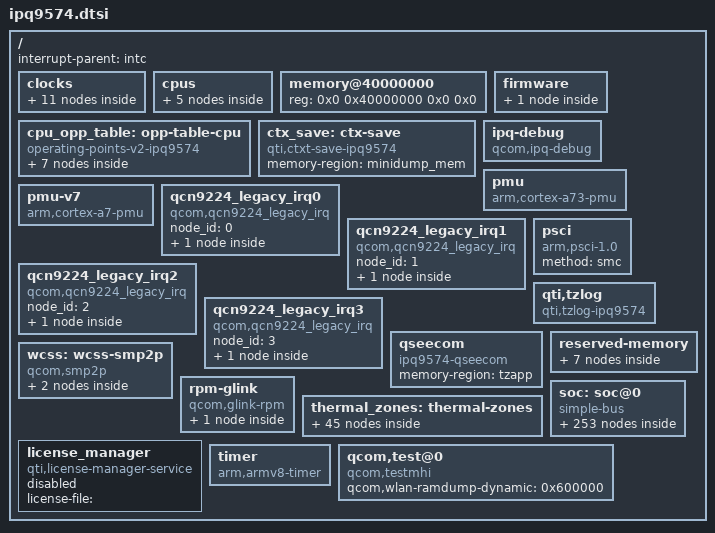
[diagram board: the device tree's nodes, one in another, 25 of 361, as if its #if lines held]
// SPDX-License-Identifier: (GPL-2.0+ OR BSD-3-Clause)
/*
 * IPQ9574 SoC device tree source
 *
 * Copyright (c) 2020-2021 The Linux Foundation. All rights reserved.
 * Copyright (c) 2022-2024 Qualcomm Innovation Center, Inc. All rights reserved.
 */

#include <dt-bindings/clock/qcom,apss-ipq.h>
#include <dt-bindings/clock/qcom,ipq9574-gcc.h>
#include <dt-bindings/interrupt-controller/arm-gic.h>
#include <dt-bindings/reset/qcom,ipq9574-gcc.h>
#include <dt-bindings/clock/qcom,nsscc-ipq9574.h>
#include <dt-bindings/reset/qcom,nsscc-ipq9574.h>


/ {
	interrupt-parent = <&intc>;
	#address-cells = <2>;
	#size-cells = <2>;

	clocks {
		bias_pll_ubi_nc_clk: bias-pll-ubi-nc-clk {
			compatible = "fixed-clock";
			clock-frequency = <353000000>;
			#clock-cells = <0>;
		};

		pcie30_phy0_pipe_clk: pcie30_phy0_pipe_clk {
			compatible = "fixed-clock";
			clock-frequency = <250000000>;
			#clock-cells = <0>;
		};

		pcie30_phy1_pipe_clk: pcie30_phy1_pipe_clk {
			compatible = "fixed-clock";
			clock-frequency = <250000000>;
			#clock-cells = <0>;
		};

		pcie30_phy2_pipe_clk: pcie30_phy2_pipe_clk {
			compatible = "fixed-clock";
			clock-frequency = <250000000>;
			#clock-cells = <0>;
		};

		pcie30_phy3_pipe_clk: pcie30_phy3_pipe_clk {
			compatible = "fixed-clock";
			clock-frequency = <250000000>;
			#clock-cells = <0>;
		};

		sleep_clk: sleep-clk {
			compatible = "fixed-clock";
			#clock-cells = <0>;
		};

		usb3phy_0_cc_pipe_clk: usb3phy_0_cc_pipe_clk {
			compatible = "fixed-clock";
			clock-frequency = <125000000>;
			#clock-cells = <0>;
		};

		xo: xo {
			compatible = "fixed-clock";
			#clock-cells = <0>;
		};

		bias_pll_cc_clk: bias_pll_cc_clk {
			compatible = "fixed-clock";
			clock-frequency = <1200000000>;
			#clock-cells = <0>;
		};

		bias_pll_nss_noc_clk: bias_pll_nss_noc_clk {
			compatible = "fixed-clock";
			clock-frequency = <461500000>;
			#clock-cells = <0>;
		};

		gcc_gpll0_out_aux: gcc_gpll0_out_aux {
			compatible = "fixed-clock";
			clock-frequency = <800000000>;
			#clock-cells = <0>;
		};
	};

	cpus {
		#address-cells = <1>;
		#size-cells = <0>;

		CPU0: cpu@0 {
			device_type = "cpu";
			compatible = "arm,cortex-a73";
			reg = <0x0>;
			enable-method = "psci";
			next-level-cache = <&L2_0>;
			clocks = <&apcs_glb APCS_ALIAS0_CORE_CLK>;
			clock-names = "cpu";
			operating-points-v2 = <&cpu_opp_table>;
			#cooling-cells = <2>;
		};

		CPU1: cpu@1 {
			device_type = "cpu";
			compatible = "arm,cortex-a73";
			reg = <0x1>;
			enable-method = "psci";
			next-level-cache = <&L2_0>;
			clocks = <&apcs_glb APCS_ALIAS0_CORE_CLK>;
			clock-names = "cpu";
			operating-points-v2 = <&cpu_opp_table>;
			#cooling-cells = <2>;
		};

		CPU2: cpu@2 {
			device_type = "cpu";
			compatible = "arm,cortex-a73";
			reg = <0x2>;
			enable-method = "psci";
			next-level-cache = <&L2_0>;
			clocks = <&apcs_glb APCS_ALIAS0_CORE_CLK>;
			clock-names = "cpu";
			operating-points-v2 = <&cpu_opp_table>;
			#cooling-cells = <2>;
		};

		CPU3: cpu@3 {
			device_type = "cpu";
			compatible = "arm,cortex-a73";
			reg = <0x3>;
			enable-method = "psci";
			next-level-cache = <&L2_0>;
			clocks = <&apcs_glb APCS_ALIAS0_CORE_CLK>;
			clock-names = "cpu";
			operating-points-v2 = <&cpu_opp_table>;
			#cooling-cells = <2>;
		};

		L2_0: l2-cache {
			compatible = "cache";
			cache-level = <2>;
		};
	};

	memory@40000000 {
		device_type = "memory";
		/* We expect the bootloader to fill in the size */
		reg = <0x0 0x40000000 0x0 0x0>;
	};

	cpu_opp_table: opp-table-cpu {
		compatible = "operating-points-v2-ipq9574";
		opp-shared;
		nvmem-cells = <&cpu_speed_bin>;
		nvmem-cell-names = "speed_bin";

		/* Listed all supported CPU frequencies and opp-supported-hw
		 * values to select CPU frequencies based on the limits fused.
		 * ------------------------------------------------------------
		 * Frequency     BIT3   BIT2   BIT1    BIT0    opp-supported-hw
		 *              1.2GHz 1.5GHz 1.8GHz No Limit
		 * ------------------------------------------------------------
		 * 936000000      1      1      1       1            0xF
		 * 1104000000     1      1      1       1            0xF
		 * 1200000000     1      0      0       0            0x8
		 * 1416000000     0      1      1       1            0x7
		 * 1488000000     0      1      0       0            0x4
		 * 1800000000     0      0      1       1            0x3
		 * 2208000000     0      0      0       1            0x1
		 * -----------------------------------------------------------*/

		opp-936000000 {
			opp-hz = /bits/ 64 <936000000>;
			opp-microvolt = <1>;
			opp-supported-hw = <0xF>;
			clock-latency-ns = <200000>;
		};

		opp-1104000000 {
			opp-hz = /bits/ 64 <1104000000>;
			opp-microvolt = <2>;
			opp-supported-hw = <0xF>;
			clock-latency-ns = <200000>;
		};

		opp-1200000000 {
			opp-hz = /bits/ 64 <1200000000>;
			opp-microvolt = <3>;
			opp-supported-hw = <0x8>;
			clock-latency-ns = <200000>;
		};

		opp-1416000000 {
			opp-hz = /bits/ 64 <1416000000>;
			opp-microvolt = <3>;
			opp-supported-hw = <0x7>;
			clock-latency-ns = <200000>;
		};

		opp-1488000000 {
			opp-hz = /bits/ 64 <1488000000>;
			opp-microvolt = <4>;
			opp-supported-hw = <0x7>;
			clock-latency-ns = <200000>;
		};

		opp-1800000000 {
			opp-hz = /bits/ 64 <1800000000>;
			opp-microvolt = <5>;
			opp-supported-hw = <0x3>;
			clock-latency-ns = <200000>;
		};

		opp-2208000000 {
			opp-hz = /bits/ 64 <2208000000>;
			opp-microvolt = <6>;
			opp-supported-hw = <0x1>;
			clock-latency-ns = <200000>;
		};
	};

	ctx_save: ctx-save {
		compatible = "qti,ctxt-save-ipq9574";
		memory-region = <&minidump_mem>;
	};

	firmware {
		scm {
			compatible = "qcom,scm-ipq9574", "qcom,scm";
			hvc-log-cmd-id = <0xA>;
			smmu-state-cmd-id = <0x20>;
			qcom,dload-mode = <&tcsr 0x6100>;
		};
	};

	ipq-debug {
		compatible = "qcom,ipq-debug";
	};

	pmu {
		compatible = "arm,cortex-a73-pmu";
		interrupts = <GIC_PPI 7 (GIC_CPU_MASK_SIMPLE(4) | IRQ_TYPE_LEVEL_HIGH)>;
	};

	pmu-v7 {
		compatible = "arm,cortex-a7-pmu";
		interrupts = <GIC_PPI 7 (GIC_CPU_MASK_SIMPLE(4) | IRQ_TYPE_LEVEL_HIGH)>;
	};

        qcn9224_legacy_irq0: qcn9224_legacy_irq0 {
		compatible = "qcom,qcn9224_legacy_irq";
		node_id = <0>;
		status = "okay";

		qcn9224_in0: legacy_interrupt {
			interrupt-controller;
			#interrupt-cells = <2>;
		};
	};

	qcn9224_legacy_irq1: qcn9224_legacy_irq1 {
		compatible = "qcom,qcn9224_legacy_irq";
		node_id = <1>;
		status = "okay";

		qcn9224_in1: legacy_interrupt {
			interrupt-controller;
			#interrupt-cells = <2>;
		};
	};

	qcn9224_legacy_irq2: qcn9224_legacy_irq2 {
		compatible = "qcom,qcn9224_legacy_irq";
		node_id = <2>;
		status = "okay";

		qcn9224_in2: legacy_interrupt {
			interrupt-controller;
			#interrupt-cells = <2>;
		};
	};

	qcn9224_legacy_irq3: qcn9224_legacy_irq3 {
		compatible = "qcom,qcn9224_legacy_irq";
		node_id = <3>;
		status = "okay";

		qcn9224_in3: legacy_interrupt {
			interrupt-controller;
			#interrupt-cells = <2>;
		};
	};

	psci {
		compatible = "arm,psci-1.0";
		method = "smc";
	};

	qti,tzlog {
		compatible = "qti,tzlog-ipq9574";
		interrupts = <GIC_SPI 244 IRQ_TYPE_EDGE_RISING>;
		qti,tz-diag-buf-size = <0x3000>;
		qti,tz-ring-off = <7>;
		qti,tz-log-pos-info-off = <810>;
		qti,hvc-enabled;
		qti,get-smmu-state;
	};

	qseecom: qseecom {
		compatible = "ipq9574-qseecom";
		memory-region = <&tzapp>;
		status = "okay";
	};

	reserved-memory {
		#address-cells = <2>;
		#size-cells = <2>;
		ranges;

		nss@40000000 {
			no-map;
			reg = <0x0 0x40000000 0x0 0x02000000>;
			status = "disabled";
		};

		tzapp:tzapp@49600000 {  /* TZAPPS */
		#if !defined(__IPQ_MEM_PROFILE_512_MB__)
			reg = <0x0 0x49600000 0x0 0x00600000>;
		#endif
			no-map;
		};

		bootloader@4a000000 {
			reg = <0x0 0x4a000000 0x0 0x00500000>;
			no-map;
		};

		sbl@4a500000 {
			reg = <0x0 0x4a500000 0x0 0x00100000>;
			no-map;
		};

		tz_region: tz@4a600000 {
			reg = <0x0 0x4a600000 0x0 0x400000>;
			no-map;
		};

		smem@4aa00000 {
			compatible = "qcom,smem";
			reg = <0x0 0x4aa00000 0x0 0x00100000>;
			hwlocks = <&tcsr_mutex 3>;
			no-map;
		};

		minidump_mem: minidump_mem@0 {
			no-map;
		};
	};

	wcss: wcss-smp2p {
		compatible = "qcom,smp2p";
		qcom,smem = <435>, <428>;

		interrupt-parent = <&intc>;
		interrupts = <GIC_SPI 322 IRQ_TYPE_EDGE_RISING>;

		mboxes = <&apcs_glb 9>;

		qcom,local-pid = <0>;
		qcom,remote-pid = <1>;

		wcss_smp2p_out: master-kernel {
			qcom,entry-name = "master-kernel";
			#qcom,smem-state-cells = <1>;
		};

		wcss_smp2p_in: slave-kernel {
			qcom,entry-name = "slave-kernel";
			interrupt-controller;
			#interrupt-cells = <2>;
		};
	};

	rpm-glink {
		compatible = "qcom,glink-rpm";
		interrupts = <GIC_SPI 168 IRQ_TYPE_EDGE_RISING>;
		qcom,rpm-msg-ram = <&rpm_msg_ram>;
		mboxes = <&apcs_glb 0>;

		rpm_requests: rpm-requests {
			compatible = "qcom,rpm-ipq9574";
			qcom,glink-channels = "rpm_requests";

		};
	};

	soc: soc@0 {
		compatible = "simple-bus";
		#address-cells = <1>;
		#size-cells = <1>;
		ranges = <0 0 0 0xffffffff>;

		qfprom {
			compatible = "qcom,qfprom-ipq9574-sec";
			img-addr = <0x4a100000>;
			img-size = <0x500000>;
			scm-cmd-id = <0x1f>;
			reg = <0xA6044 0x4>;
		};

		reg_update: reg-update@400000 {
			compatible = "ipq,reg-update";
			reg = <0x00400000 0x6148>,
			      <0x39d00020 0x10>;
			reg-names = "memnoc",
				    "ubicore";
			clocks = <&nsscc NSS_CC_NSS_CSR_CLK>,
				 <&nsscc NSS_CC_NSSNOC_NSS_CSR_CLK>;
			clock-names = "nss-csr-clk",
				      "nss-nssnoc-csr-clk";
			assigned-clocks = <&nsscc NSS_CC_NSS_CSR_CLK>,
					  <&nsscc NSS_CC_NSSNOC_NSS_CSR_CLK>;
			assigned-clock-rates = <100000000>,
					       <100000000>;
			status = "okay";
		};

		pcie0_phy: phy@84000 {
			compatible = "qcom,ipq9574-qmp-gen3x1-pcie-phy";
			reg = <0x00084000 0x1bc>; /* Serdes PLL */
			#address-cells = <1>;
			#size-cells = <1>;
			ranges;
			clocks = <&gcc GCC_PCIE0_AUX_CLK>,
				 <&gcc GCC_PCIE0_AHB_CLK>,
				 <&gcc GCC_ANOC_PCIE0_1LANE_M_CLK>,
				 <&gcc GCC_SNOC_PCIE0_1LANE_S_CLK>;
			clock-names = "aux", "cfg_ahb", "anoc_lane", "snoc_lane";

			assigned-clocks = <&gcc GCC_PCIE0_AUX_CLK>,
					  <&gcc GCC_PCIE0_AHB_CLK>,
					  <&gcc GCC_ANOC_PCIE0_1LANE_M_CLK>,
					  <&gcc GCC_SNOC_PCIE0_1LANE_S_CLK>;
			assigned-clock-rates = <20000000>,
					       <100000000>,
					       <240000000>,
					       <240000000>;

			resets = <&gcc GCC_PCIE0_PHY_BCR>,
				 <&gcc GCC_PCIE0PHY_PHY_BCR>;
			reset-names = "phy", "common";

			status = "disabled";

			pcie0_lane: phy@84200 {
				reg = <0x00084200 0x16c>, /* Serdes Tx */
				      <0x00084400 0x200>, /* Serdes Rx */
				      <0x00084800 0x1f0>, /* PCS: Lane0, COM, PCIE */
				      <0x00084c00 0xf4>;  /* pcs_misc */
				#phy-cells = <0>;

				clocks = <&gcc GCC_PCIE0_PIPE_CLK>;
				clock-names = "pipe0";
				clock-output-names = "gcc_pcie0_pipe_clk_src";
				#clock-cells = <0>;
			};
		};

		pcie2_phy: phy@8c000 {
			compatible = "qcom,ipq9574-qmp-gen3x2-pcie-phy";
			reg = <0x0008c000 0x1bc>; /* Serdes PLL */
			#address-cells = <1>;
			#size-cells = <1>;
			ranges;

			clocks = <&gcc GCC_PCIE2_AUX_CLK>,
				 <&gcc GCC_PCIE2_AHB_CLK>,
				 <&gcc GCC_ANOC_PCIE2_2LANE_M_CLK>,
				 <&gcc GCC_SNOC_PCIE2_2LANE_S_CLK>;
			clock-names = "aux", "cfg_ahb", "anoc_lane", "snoc_lane";

			assigned-clocks = <&gcc GCC_PCIE2_AUX_CLK>,
					  <&gcc GCC_PCIE2_AHB_CLK>,
					  <&gcc GCC_ANOC_PCIE2_2LANE_M_CLK>,
					  <&gcc GCC_SNOC_PCIE2_2LANE_S_CLK>;
			assigned-clock-rates = <20000000>,
					       <100000000>,
					       <342857143>,
					       <240000000>;

			resets = <&gcc GCC_PCIE2_PHY_BCR>,
				 <&gcc GCC_PCIE2PHY_PHY_BCR>;
			reset-names = "phy", "common";

			status = "disabled";

			pcie2_lanes: phy@8c200 {
				reg = <0x0008c200 0x16c>, /* Serdes Tx0 */
				      <0x0008c400 0x200>, /* Serdes Rx0 */
				      <0x0008d000 0x1f0>, /* PCS: Lane0, COM, PCIE */
				      <0x0008c600 0x16c>, /* Serdes Tx1 */
				      <0x0008c800 0x200>, /* Serdes Rx1 */
				      <0x0008d400 0x0f8>; /* pcs_misc */

				#phy-cells = <0>;

				clocks = <&gcc GCC_PCIE2_PIPE_CLK>;
				clock-names = "pipe0";
				clock-output-names = "gcc_pcie2_pipe_clk_src";
				#clock-cells = <0>;
			};
		};

		pcie3_phy: phy@f4000 {
			compatible = "qcom,ipq9574-qmp-gen3x2-pcie-phy";
			reg = <0x000f4000 0x1bc>; /* Serdes PLL */
			#address-cells = <1>;
			#size-cells = <1>;
			ranges;

			clocks = <&gcc GCC_PCIE3_AUX_CLK>,
				 <&gcc GCC_PCIE3_AHB_CLK>,
				 <&gcc GCC_ANOC_PCIE3_2LANE_M_CLK>,
				 <&gcc GCC_SNOC_PCIE3_2LANE_S_CLK>;
			clock-names = "aux", "cfg_ahb", "anoc_lane", "snoc_lane";

			assigned-clocks = <&gcc GCC_PCIE3_AUX_CLK>,
					  <&gcc GCC_PCIE3_AHB_CLK>,
					  <&gcc GCC_ANOC_PCIE3_2LANE_M_CLK>,
					  <&gcc GCC_SNOC_PCIE3_2LANE_S_CLK>;
			assigned-clock-rates = <20000000>,
					       <100000000>,
					       <342857143>,
					       <240000000>;

			resets = <&gcc GCC_PCIE3_PHY_BCR>,
				 <&gcc GCC_PCIE3PHY_PHY_BCR>;
			reset-names = "phy", "common";

			status = "disabled";

			pcie3_lanes: phy@f4200 {
				reg = <0x000f4200 0x16c>, /* Serdes Tx0 */
				      <0x000f4400 0x200>, /* Serdes Rx0 */
				      <0x000f5000 0x1f0>, /* PCS: Lane0, COM, PCIE */
				      <0x000f4600 0x16c>, /* Serdes Tx1 */
				      <0x000f4800 0x200>, /* Serdes Rx1 */
				      <0x000f5400 0x0f8>; /* pcs_misc */

				#phy-cells = <0>;

				clocks = <&gcc GCC_PCIE3_PIPE_CLK>;
				clock-names = "pipe0";
				clock-output-names = "gcc_pcie3_pipe_clk_src";
				#clock-cells = <0>;
			};
		};

		pcie1_phy: phy@fc000 {
			compatible = "qcom,ipq9574-qmp-gen3x1-pcie-phy";
			reg = <0x000fc000 0x1bc>; /* Serdes PLL */
			#address-cells = <1>;
			#size-cells = <1>;
			ranges;

			clocks = <&gcc GCC_PCIE1_AUX_CLK>,
			 <&gcc GCC_PCIE1_AHB_CLK>,
			 <&gcc GCC_ANOC_PCIE1_1LANE_M_CLK>,
				 <&gcc GCC_SNOC_PCIE1_1LANE_S_CLK>;
			clock-names = "aux", "cfg_ahb", "anoc_lane", "snoc_lane";

			assigned-clocks = <&gcc GCC_PCIE1_AUX_CLK>,
					  <&gcc GCC_PCIE1_AHB_CLK>,
					  <&gcc GCC_ANOC_PCIE1_1LANE_M_CLK>,
					  <&gcc GCC_SNOC_PCIE1_1LANE_S_CLK>;
			assigned-clock-rates = <20000000>,
					       <100000000>,
					       <240000000>,
					       <240000000>;

			resets = <&gcc GCC_PCIE1_PHY_BCR>,
				 <&gcc GCC_PCIE1PHY_PHY_BCR>;
			reset-names = "phy", "common";

			status = "disabled";

			pcie1_lane: phy@fc200 {
				reg = <0x000fc200 0x16c>, /* Serdes Tx */
				      <0x000fc400 0x200>, /* Serdes Rx */
				      <0x000fc800 0x1f0>, /* PCS: Lane0, COM, PCIE */
				      <0x000fcc00 0xf4>;  /* pcs_misc */
				#phy-cells = <0>;

				clocks = <&gcc GCC_PCIE1_PIPE_CLK>;
				clock-names = "pipe0";
				clock-output-names = "gcc_pcie1_pipe_clk_src";
				#clock-cells = <0>;
			};
		};

		qfprom@a4000 {
			compatible = "qcom,qfprom";
			reg = <0xA4000 0x5a1>;
			#address-cells = <1>;
			#size-cells = <1>;

			cpu_speed_bin: cpu_speed_bin@15 {
				reg = <0x15 0x2>;
				bits = <7 2>;
			};

			pcie0_disable: pcie0_disable@1c {
				reg = <0x1c 0x1>;
				bits = <2 1>;
			};

			pcie1_disable: pcie1_disable@1c {
				reg = <0x1c 0x1>;
				bits = <3 1>;
			};

			pcie2_disable: pcie2_disable@1c {
				reg = <0x1c 0x1>;
				bits = <4 1>;
			};

			pcie3_disable: pcie3_disable@1c {
				reg = <0x1c 0x1>;
				bits = <5 1>;
			};
		};

		rng: rng@e3000 {
			compatible = "qcom,prng-ee";
			reg = <0x000e3000 0x1000>;
			clocks = <&gcc GCC_PRNG_AHB_CLK>;
			clock-names = "core";
		};

		cryptobam: dma@704000 {
			compatible = "qcom,bam-v1.7.0";
			reg = <0x00704000 0x20000>;
			interrupts = <GIC_SPI 207 IRQ_TYPE_LEVEL_HIGH>;
			#dma-cells = <1>;
			qcom,ee = <1>;
			qcom,controlled-remotely;
		};

		crypto: crypto@73a000 {
			compatible = "qcom,crypto-v5.1";
			reg = <0x0073a000 0x6000>;
			clocks = <&gcc GCC_CRYPTO_AHB_CLK>,
				 <&gcc GCC_CRYPTO_AXI_CLK>,
				 <&gcc GCC_CRYPTO_CLK>;
			clock-names = "iface", "bus", "core";
			dmas = <&cryptobam 2>, <&cryptobam 3>;
			dma-names = "rx", "tx";
			qce,cmd_desc_support;
		};

		rpm_msg_ram: sram@60000 {
			compatible = "qcom,rpm-msg-ram";
			reg = <0x00060000 0x6000>;
		};

		tsens: thermal-sensor@4a9000 {
			compatible = "qcom,ipq9574-tsens", "qcom,ipq8074-tsens";
			reg = <0x004a9000 0x1000>,
			      <0x004a8000 0x1000>;
			interrupts = <GIC_SPI 184 IRQ_TYPE_EDGE_RISING>;
			interrupt-names = "combined";
			#qcom,sensors = <16>;
			#thermal-sensor-cells = <1>;
		};

		tlmm: pinctrl@1000000 {
			compatible = "qcom,ipq9574-tlmm";
			reg = <0x01000000 0x300000>;
			interrupts = <GIC_SPI 208 IRQ_TYPE_LEVEL_HIGH>;
			gpio-controller;
			#gpio-cells = <2>;
			gpio-ranges = <&tlmm 0 0 65>;
			interrupt-controller;
			#interrupt-cells = <2>;

			uart2_pins: uart2-state {
				pins = "gpio34", "gpio35";
				function = "blsp2_uart";
				drive-strength = <8>;
				bias-disable;
			};

			gps_pins: gps_pins {
                                blsp3_uart_pinmux {
                                        pins = "gpio17", "gpio18";
                                        function = "blsp3_uart";
                                        drive-strength = <8>;
                                        bias-disable;
                                };

                                gps_on_off {
                                        pins = "gpio7";
                                        function = "gpio";
                                        drive-strength = <8>;
                                        bias-pull-down;
                                };
                        };

			mdio_pins: mdio-state {
				mux_0 {
					pins = "gpio38";
					function = "mdc";
					drive-strength = <8>;
					bias-disable;
				};

				mux_1 {
					pins = "gpio39";
					function = "mdio";
					drive-strength = <8>;
					bias-pull-up;
				};
			};
		};

		gcc: clock-controller@1800000 {
			compatible = "qcom,ipq9574-gcc";
			reg = <0x01800000 0x80000>;
			clocks = <&xo>,
				 <&sleep_clk>,
				 <&bias_pll_ubi_nc_clk>,
				 <&pcie30_phy0_pipe_clk>,
				 <&pcie30_phy1_pipe_clk>,
				 <&pcie30_phy2_pipe_clk>,
				 <&pcie30_phy3_pipe_clk>,
				 <&usb3phy_0_cc_pipe_clk>;
			#clock-cells = <1>;
			#reset-cells = <1>;
			#power-domain-cells = <1>;
		};

                nsscc: nsscc@39b00000 {
			compatible = "qcom,nsscc-ipq9574";
			reg = <0x39b00000 0x80000>;
			clocks = <&bias_pll_cc_clk>,
				 <&bias_pll_nss_noc_clk>,
				 <&bias_pll_ubi_nc_clk>,
				 <&gcc_gpll0_out_aux>,
				 <&xo>;
			clock-names = "bias_pll_cc_clk",
				      "bias_pll_nss_noc_clk",
				      "bias_pll_ubi_nc_clk",
				      "gcc_gpll0_out_aux",
				      "xo";
			#clock-cells = <0x1>;
			#reset-cells = <0x1>;
		};

		dcc@797f000 {
			compatible = "qcom,dcc-v2";
			reg = <0x797F000 0x1000>,
			      <0x7906000 0x1000>;
			reg-names = "dcc-base", "dcc-ram-base";

			dcc-ram-offset = <0x6000>;
			status = "okay";
		};

		qpic_bam: dma@7984000 {
			compatible = "qcom,bam-v1.7.0";
			reg = <0x7984000 0x1c000>;
			interrupts = <GIC_SPI 146 IRQ_TYPE_LEVEL_HIGH>;
			clocks = <&gcc GCC_QPIC_AHB_CLK>;
			clock-names = "bam_clk";
			#dma-cells = <1>;
			qcom,ee = <0>;
			status = "disabled";
		};

		qpic_nand: nand@79b0000 {
			compatible = "qcom,ipq9574-nand";
			reg = <0x79b0000 0x10000>;
			#address-cells = <1>;
			#size-cells = <0>;
			clocks = <&gcc GCC_QPIC_CLK>,
			<&gcc GCC_QPIC_AHB_CLK>,
			<&gcc GCC_QPIC_IO_MACRO_CLK>;
			clock-names = "core", "aon", "io_macro";

			dmas = <&qpic_bam 0>,
				<&qpic_bam 1>,
				<&qpic_bam 2>,
				<&qpic_bam 3>;
			dma-names = "tx", "rx", "cmd", "sts";
			status = "disabled";
		};

		lpass: lpass@0xA000000{
			compatible = "qca,lpass-ipq9574";
			reg =  <0xA000000 0x3BFFFF>;
			clocks = <&gcc GCC_LPASS_SWAY_CLK>,
			<&gcc GCC_LPASS_CORE_AXIM_CLK>,
			<&gcc GCC_SNOC_LPASS_CFG_CLK>,
			<&gcc GCC_PCNOC_LPASS_CLK>;
			clock-names = "sway", "axim", "snoc_cfg", "pcnoc";
			resets = <&gcc GCC_LPASS_BCR>;
			reset-names = "lpass";
			status = "disabled";
		};

		pcm: pcm@0xA3C0000{
			compatible = "qca,ipq9574-lpass-pcm";
			reg =  <0xA3C0000 0x23014>;
			status = "disabled";

			pcm0: pcm0@0 {
				interrupts = <0 419 IRQ_TYPE_LEVEL_HIGH>;
				interrupt-names = "out0";
				capture_memory = "lpm";
				playback_memory = "lpm";
				voice_loopback = <0>;
				slave = <0>;
				status = "disabled";
			      };

			pcm1: pcm1@1 {
				interrupts = <0 117 IRQ_TYPE_LEVEL_HIGH>;
				interrupt-names = "out1";
				capture_memory = "lpm";
				playback_memory = "lpm";
				voice_loopback = <0>;
				slave = <0>;
				status = "disabled";
			};

		};

		pcm_lb: pcm_lb@0 {
			compatible = "qca,ipq9574-pcm-lb";
			status = "disabled";
		};

		wsi: wsi {
			status = "disabled";
		};

		pcie1_x1: pci@10000000 {
			compatible = "qti,pcie-ipq9574";
			reg =  <0x10000000 0xf1d>,
			       <0x10000F20 0xa8>,
			       <0x10001000 0x1000>,
			       <0x000F8000 0x4000>,
			       <0x10100000 0x1000>,
			       <0x00618108 0x4>;
			reg-names = "dbi", "elbi", "atu", "parf", "config", "aggr_noc";
			device_type = "pci";
			linux,pci-domain = <1>;
			bus-range = <0x00 0xff>;
			num-lanes = <1>;
			#address-cells = <3>;
			#size-cells = <2>;
			axi-halt-val = <0x1e>; /* increase halt window size to 1GB */

			ranges = <0x81000000 0 0x10200000 0x10200000
				  0 0x00100000   /* downstream I/O */
				  0x82000000 0 0x10300000 0x10300000
				  0 0x07d00000>; /* non-prefetchable memory */

			#interrupt-cells = <1>;
			interrupt-map-mask = <0 0 0 0x7>;
			interrupt-map = <0 0 0 1 &intc 0 35
					IRQ_TYPE_LEVEL_HIGH>, /* int_a */
					<0 0 0 2 &intc 0 49
					IRQ_TYPE_LEVEL_HIGH>, /* int_b */
					<0 0 0 3 &intc 0 84
					IRQ_TYPE_LEVEL_HIGH>, /* int_c */
					<0 0 0 4 &intc 0 85
					IRQ_TYPE_LEVEL_HIGH>; /* int_d */

			interrupts = <GIC_SPI 25 IRQ_TYPE_LEVEL_HIGH>;
			interrupt-names = "global_irq";

			/* clocks and clock-names are used to enable the clock in CBCR */
			clocks = <&gcc GCC_PCIE1_AHB_CLK>,
				 <&gcc GCC_PCIE1_AUX_CLK>,
				 <&gcc GCC_PCIE1_AXI_M_CLK>,
				 <&gcc GCC_PCIE1_AXI_S_CLK>,
				 <&gcc GCC_PCIE1_AXI_S_BRIDGE_CLK>,
				 <&gcc GCC_PCIE1_RCHNG_CLK>;
			clock-names = "ahb",
				      "aux",
				      "axi_m",
				      "axi_s",
				      "axi_bridge",
				      "rchng";

			assigned-clocks = <&gcc GCC_PCIE1_AHB_CLK>,
					  <&gcc GCC_PCIE1_AUX_CLK>,
				    	  <&gcc GCC_PCIE1_AXI_M_CLK>,
					  <&gcc GCC_PCIE1_AXI_S_CLK>,
					  <&gcc GCC_PCIE1_AXI_S_BRIDGE_CLK>,
					  <&gcc GCC_PCIE1_RCHNG_CLK>;
			assigned-clock-rates = <100000000>,
					       <20000000>,
					       <240000000>,
					       <240000000>,
					       <240000000>,
					       <100000000>;

			resets = <&gcc GCC_PCIE1_PIPE_ARES>,
				 <&gcc GCC_PCIE1_CORE_STICKY_ARES>,
				 <&gcc GCC_PCIE1_AXI_S_STICKY_ARES>,
				 <&gcc GCC_PCIE1_AXI_S_ARES>,
				 <&gcc GCC_PCIE1_AXI_M_STICKY_ARES>,
				 <&gcc GCC_PCIE1_AXI_M_ARES>,
				 <&gcc GCC_PCIE1_AUX_ARES>,
				 <&gcc GCC_PCIE1_AHB_ARES>;
			reset-names = "pipe",
				      "sticky",
				      "axi_s_sticky",
				      "axi_s",
				      "axi_m_sticky",
				      "axi_m",
				      "aux",
				      "ahb";

			phys = <&pcie1_lane>;
			phy-names = "pciephy";
			msi-parent = <&v2m0>;
			nvmem-cells = <&pcie1_disable>;
			status = "disabled";
		};

		pcie3_x2: pci@18000000 {
			compatible = "qti,pcie-ipq9574";
			reg =  <0x18000000 0xf1d>,
			       <0x18000F20 0xa8>,
			       <0x18001000 0x1000>,
			       <0x000F0000 0x4000>,
			       <0x18100000 0x1000>;
			reg-names = "dbi", "elbi", "atu", "parf", "config";
			device_type = "pci";
			linux,pci-domain = <3>;
			bus-range = <0x00 0xff>;
			num-lanes = <2>;
			#address-cells = <3>;
			#size-cells = <2>;
			axi-halt-val = <0x1e>; /* increase halt window size to 1GB */

			ranges = <0x81000000 0 0x18200000 0x18200000
				  0 0x00100000   /* downstream I/O */
				  0x82000000 0 0x18300000 0x18300000
				  0 0x07d00000>; /* non-prefetchable memory */

			#interrupt-cells = <1>;
			interrupt-map-mask = <0 0 0 0x7>;
			interrupt-map = <0 0 0 1 &intc 0 189
					 IRQ_TYPE_LEVEL_HIGH>, /* int_a */
					<0 0 0 2 &intc 0 190
					 IRQ_TYPE_LEVEL_HIGH>, /* int_b */
					<0 0 0 3 &intc 0 191
					 IRQ_TYPE_LEVEL_HIGH>, /* int_c */
					<0 0 0 4 &intc 0 192
					 IRQ_TYPE_LEVEL_HIGH>; /* int_d */

			interrupts = <GIC_SPI 188 IRQ_TYPE_LEVEL_HIGH>;
			interrupt-names = "global_irq";

			/* clocks and clock-names are used to enable the clock in CBCR */
			clocks = <&gcc GCC_PCIE3_AHB_CLK>,
				 <&gcc GCC_PCIE3_AUX_CLK>,
				 <&gcc GCC_PCIE3_AXI_M_CLK>,
				 <&gcc GCC_PCIE3_AXI_S_CLK>,
				 <&gcc GCC_PCIE3_AXI_S_BRIDGE_CLK>,
				 <&gcc GCC_PCIE3_RCHNG_CLK>;
			clock-names = "ahb",
				      "aux",
				      "axi_m",
				      "axi_s",
				      "axi_bridge",
				      "rchng";

			assigned-clocks = <&gcc GCC_PCIE3_AHB_CLK>,
					  <&gcc GCC_PCIE3_AUX_CLK>,
					  <&gcc GCC_PCIE3_AXI_M_CLK>,
					  <&gcc GCC_PCIE3_AXI_S_CLK>,
					  <&gcc GCC_PCIE3_AXI_S_BRIDGE_CLK>,
					  <&gcc GCC_PCIE3_RCHNG_CLK>;
			assigned-clock-rates = <100000000>,
					       <20000000>,
					       <342857143>,
					       <240000000>,
					       <240000000>,
					       <100000000>;

			resets = <&gcc GCC_PCIE3_PIPE_ARES>,
				 <&gcc GCC_PCIE3_CORE_STICKY_ARES>,
				 <&gcc GCC_PCIE3_AXI_S_STICKY_ARES>,
				 <&gcc GCC_PCIE3_AXI_S_ARES>,
				 <&gcc GCC_PCIE3_AXI_M_STICKY_ARES>,
				 <&gcc GCC_PCIE3_AXI_M_ARES>,
				 <&gcc GCC_PCIE3_AUX_ARES>,
				 <&gcc GCC_PCIE3_AHB_ARES>;
			reset-names = "pipe",
				      "sticky",
				      "axi_s_sticky",
				      "axi_s",
				      "axi_m_sticky",
				      "axi_m",
				      "aux",
				      "ahb";

			phys = <&pcie3_lanes>;
			phy-names = "pciephy";
			msi-parent = <&v2m0>;
			nvmem-cells = <&pcie3_disable>;
			status = "disabled";
		};

		pcie2_x2: pci@20000000 {
			compatible = "qti,pcie-ipq9574";
			reg =  <0x20000000 0xf1d>,
			       <0x20000F20 0xa8>,
			       <0x20001000 0x1000>,
			       <0x00088000 0x4000>,
			       <0x20100000 0x1000>;
			reg-names = "dbi", "elbi", "atu", "parf", "config";
			device_type = "pci";
			linux,pci-domain = <2>;
			bus-range = <0x00 0xff>;
			num-lanes =<2>;
			#address-cells = <3>;
			#size-cells = <2>;
			axi-halt-val = <0x1e>; /* increase halt window size to 1GB */

			ranges = <0x81000000 0 0x20200000 0x20200000
				  0 0x00100000   /* downstream I/O */
				  0x82000000 0 0x20300000 0x20300000
				  0 0x07d00000>; /* non-prefetchable memory */

			#interrupt-cells = <1>;
			interrupt-map-mask = <0 0 0 0x7>;
			interrupt-map = <0 0 0 1 &intc 0 164
					 IRQ_TYPE_LEVEL_HIGH>, /* int_a */
					<0 0 0 2 &intc 0 165
					 IRQ_TYPE_LEVEL_HIGH>, /* int_b */
					<0 0 0 3 &intc 0 186
					 IRQ_TYPE_LEVEL_HIGH>, /* int_c */
					<0 0 0 4 &intc 0 187
					 IRQ_TYPE_LEVEL_HIGH>; /* int_d */

			interrupts = <GIC_SPI 125 IRQ_TYPE_LEVEL_HIGH>;
			interrupt-names = "global_irq";

			/* clocks and clock-names are used to enable the clock in CBCR */
			clocks = <&gcc GCC_PCIE2_AHB_CLK>,
				 <&gcc GCC_PCIE2_AUX_CLK>,
				 <&gcc GCC_PCIE2_AXI_M_CLK>,
				 <&gcc GCC_PCIE2_AXI_S_CLK>,
				 <&gcc GCC_PCIE2_AXI_S_BRIDGE_CLK>,
				 <&gcc GCC_PCIE2_RCHNG_CLK>;
			clock-names = "ahb",
				      "aux",
				      "axi_m",
				      "axi_s",
				      "axi_bridge",
				      "rchng";

			assigned-clocks = <&gcc GCC_PCIE2_AHB_CLK>,
					  <&gcc GCC_PCIE2_AUX_CLK>,
					  <&gcc GCC_PCIE2_AXI_M_CLK>,
					  <&gcc GCC_PCIE2_AXI_S_CLK>,
					  <&gcc GCC_PCIE2_AXI_S_BRIDGE_CLK>,
					  <&gcc GCC_PCIE2_RCHNG_CLK>;
			assigned-clock-rates = <100000000>,
					       <20000000>,
					       <342857143>,
					       <240000000>,
					       <240000000>,
					       <100000000>;

			resets = <&gcc GCC_PCIE2_PIPE_ARES>,
				 <&gcc GCC_PCIE2_CORE_STICKY_ARES>,
				 <&gcc GCC_PCIE2_AXI_S_STICKY_ARES>,
				 <&gcc GCC_PCIE2_AXI_S_ARES>,
				 <&gcc GCC_PCIE2_AXI_M_STICKY_ARES>,
				 <&gcc GCC_PCIE2_AXI_M_ARES>,
				 <&gcc GCC_PCIE2_AUX_ARES>,
				 <&gcc GCC_PCIE2_AHB_ARES>;
			reset-names = "pipe",
				      "sticky",
				      "axi_s_sticky",
				      "axi_s",
				      "axi_m_sticky",
				      "axi_m",
				      "aux",
				      "ahb";

			phys = <&pcie2_lanes>;
			phy-names = "pciephy";
			msi-parent = <&v2m0>;
			nvmem-cells = <&pcie2_disable>;
			status = "disabled";
		};

		pcie0_x1: pci@28000000 {
			compatible = "qti,pcie-ipq9574";
			reg =  <0x28000000 0xf1d>,
			       <0x28000F20 0xa8>,
			       <0x28001000 0x1000>,
			       <0x00080000 0x4000>,
			       <0x28100000 0x1000>,
			       <0x00618088 0x4>;
			reg-names = "dbi", "elbi", "atu", "parf", "config", "aggr_noc";
			device_type = "pci";
			linux,pci-domain = <0>;
			bus-range = <0x00 0xff>;
			num-lanes = <1>;
			#address-cells = <3>;
			#size-cells = <2>;
			axi-halt-val = <0x1e>; /* increase halt window size to 1GB */

			ranges = <0x81000000 0 0x28200000 0x28200000
				  0 0x00100000   /* downstream I/O */
				  0x82000000 0 0x28300000 0x28300000
				  0 0x07d00000>; /* non-prefetchable memory */

			#interrupt-cells = <1>;
			interrupt-map-mask = <0 0 0 0x7>;
			interrupt-map = <0 0 0 1 &intc 0 75
					 IRQ_TYPE_LEVEL_HIGH>, /* int_a */
					<0 0 0 2 &intc 0 78
					 IRQ_TYPE_LEVEL_HIGH>, /* int_b */
					<0 0 0 3 &intc 0 79
					 IRQ_TYPE_LEVEL_HIGH>, /* int_c */
					<0 0 0 4 &intc 0 83
					 IRQ_TYPE_LEVEL_HIGH>; /* int_d */

			interrupts = <GIC_SPI 51 IRQ_TYPE_LEVEL_HIGH>;
			interrupt-names = "global_irq";

			/* clocks and clock-names are used to enable the clock in CBCR */
			clocks = <&gcc GCC_PCIE0_AHB_CLK>,
				 <&gcc GCC_PCIE0_AUX_CLK>,
				 <&gcc GCC_PCIE0_AXI_M_CLK>,
				 <&gcc GCC_PCIE0_AXI_S_CLK>,
				 <&gcc GCC_PCIE0_AXI_S_BRIDGE_CLK>,
				 <&gcc GCC_PCIE0_RCHNG_CLK>;
			clock-names = "ahb",
				      "aux",
				      "axi_m",
				      "axi_s",
				      "axi_bridge",
				      "rchng";

			assigned-clocks = <&gcc GCC_PCIE0_AHB_CLK>,
					  <&gcc GCC_PCIE0_AUX_CLK>,
					  <&gcc GCC_PCIE0_AXI_M_CLK>,
					  <&gcc GCC_PCIE0_AXI_S_CLK>,
					  <&gcc GCC_PCIE0_AXI_S_BRIDGE_CLK>,
					  <&gcc GCC_PCIE0_RCHNG_CLK>;
			assigned-clock-rates = <100000000>,
					       <20000000>,
					       <240000000>,
					       <240000000>,
					       <240000000>,
					       <100000000>;

			resets = <&gcc GCC_PCIE0_PIPE_ARES>,
				 <&gcc GCC_PCIE0_CORE_STICKY_ARES>,
				 <&gcc GCC_PCIE0_AXI_S_STICKY_ARES>,
				 <&gcc GCC_PCIE0_AXI_S_ARES>,
				 <&gcc GCC_PCIE0_AXI_M_STICKY_ARES>,
				 <&gcc GCC_PCIE0_AXI_M_ARES>,
				 <&gcc GCC_PCIE0_AUX_ARES>,
				 <&gcc GCC_PCIE0_AHB_ARES>;
			reset-names = "pipe",
				      "sticky",
				      "axi_s_sticky",
				      "axi_s",
				      "axi_m_sticky",
				      "axi_m",
				      "aux",
				      "ahb";

			phys = <&pcie0_lane>;
			phy-names = "pciephy";
			msi-parent = <&v2m0>;
			nvmem-cells = <&pcie0_disable>;
			status = "disabled";
		};

		qti,rpm-log@29fc00 {
			compatible = "qti,rpm-log";
			reg = <0x29fc00 0x4000>;
			qti,rpm-addr-phys = <0x200000>;
			qti,offset-version = <4>;
			qti,offset-page-buffer-addr = <36>;
			qti,offset-log-len = <40>;
			qti,offset-log-len-mask = <44>;
			qti,offset-page-indices = <56>;
		};

		wifi0: wifi@c0000000 {
			compatible = "qcom,cnss-qca9574", "qcom,ipq9574-wifi";
			reg = <0xc000000 0x1000000>;
			qcom,hw-mode-id = <1>;
		#ifdef __IPQ_MEM_PROFILE_256_MB__
			qcom,tgt-mem-mode = <2>;
		#elif __IPQ_MEM_PROFILE_512_MB__
			qcom,tgt-mem-mode = <1>;
		#else
			qcom,tgt-mem-mode = <0>;
		#endif
			qcom,rproc = <&q6v5_wcss>;
			qcom,bdf-addr = <0x4b700000 0x4b700000 0x4b700000
					 0x0 0x0 0x0>;
			qcom,caldb-addr = <0x4d800000 0x4ca00000 0x0
					   0x0 0x0 0x0>;
			qcom,caldb-size = <0x500000>;
		#ifdef __IPQ_MEM_PROFILE_512_MB__
			m3-dump-addr = <0x4c800000>;
		#else
			m3-dump-addr = <0x4d600000>;
		#endif
			interrupts = <GIC_SPI 320 IRQ_TYPE_EDGE_RISING>, /* o_wcss_apps_intr[0] =  */
				<GIC_SPI 319 IRQ_TYPE_EDGE_RISING>,
				<GIC_SPI 318 IRQ_TYPE_EDGE_RISING>,
				<GIC_SPI 316 IRQ_TYPE_EDGE_RISING>,
				<GIC_SPI 315 IRQ_TYPE_EDGE_RISING>,
				<GIC_SPI 314 IRQ_TYPE_EDGE_RISING>,
				<GIC_SPI 311 IRQ_TYPE_EDGE_RISING>,
				<GIC_SPI 310 IRQ_TYPE_EDGE_RISING>,
				<GIC_SPI 411 IRQ_TYPE_EDGE_RISING>,
				<GIC_SPI 410 IRQ_TYPE_EDGE_RISING>,
				<GIC_SPI 40 IRQ_TYPE_EDGE_RISING>,
				<GIC_SPI 39 IRQ_TYPE_EDGE_RISING>,
				<GIC_SPI 302 IRQ_TYPE_EDGE_RISING>,
				<GIC_SPI 301 IRQ_TYPE_EDGE_RISING>,
				<GIC_SPI 37 IRQ_TYPE_EDGE_RISING>,
				<GIC_SPI 36 IRQ_TYPE_EDGE_RISING>,
				<GIC_SPI 296 IRQ_TYPE_EDGE_RISING>,
				<GIC_SPI 295 IRQ_TYPE_EDGE_RISING>,
				<GIC_SPI 294 IRQ_TYPE_EDGE_RISING>,
				<GIC_SPI 293 IRQ_TYPE_EDGE_RISING>,
				<GIC_SPI 292 IRQ_TYPE_EDGE_RISING>,
				<GIC_SPI 291 IRQ_TYPE_EDGE_RISING>,
				<GIC_SPI 290 IRQ_TYPE_EDGE_RISING>,
				<GIC_SPI 289 IRQ_TYPE_EDGE_RISING>,
				<GIC_SPI 288 IRQ_TYPE_EDGE_RISING>, /* o_wcss_apps_intr[25] */
				<GIC_SPI 239 IRQ_TYPE_EDGE_RISING>,
				<GIC_SPI 236 IRQ_TYPE_EDGE_RISING>,
				<GIC_SPI 235 IRQ_TYPE_EDGE_RISING>,
				<GIC_SPI 234 IRQ_TYPE_EDGE_RISING>,
				<GIC_SPI 233 IRQ_TYPE_EDGE_RISING>,
				<GIC_SPI 232 IRQ_TYPE_EDGE_RISING>,
				<GIC_SPI 231 IRQ_TYPE_EDGE_RISING>,
				<GIC_SPI 230 IRQ_TYPE_EDGE_RISING>,
				<GIC_SPI 229 IRQ_TYPE_EDGE_RISING>,
				<GIC_SPI 228 IRQ_TYPE_EDGE_RISING>,
				<GIC_SPI 224 IRQ_TYPE_EDGE_RISING>,
				<GIC_SPI 223 IRQ_TYPE_EDGE_RISING>,
				<GIC_SPI 203 IRQ_TYPE_EDGE_RISING>,
				<GIC_SPI 183 IRQ_TYPE_EDGE_RISING>,
				<GIC_SPI 180 IRQ_TYPE_EDGE_RISING>,
				<GIC_SPI 179 IRQ_TYPE_EDGE_RISING>,
				<GIC_SPI 178 IRQ_TYPE_EDGE_RISING>,
				<GIC_SPI 177 IRQ_TYPE_EDGE_RISING>,
				<GIC_SPI 176 IRQ_TYPE_EDGE_RISING>,
				<GIC_SPI 163 IRQ_TYPE_EDGE_RISING>,
				<GIC_SPI 162 IRQ_TYPE_EDGE_RISING>,
				<GIC_SPI 160 IRQ_TYPE_EDGE_RISING>,
				<GIC_SPI 414 IRQ_TYPE_EDGE_RISING>,
				<GIC_SPI 159 IRQ_TYPE_EDGE_RISING>,
				<GIC_SPI 158 IRQ_TYPE_EDGE_RISING>,
				<GIC_SPI 157 IRQ_TYPE_EDGE_RISING>,
				<GIC_SPI 156 IRQ_TYPE_EDGE_RISING>; /* o_wcss_apps_intr[51] */

			interrupt-names = "misc-pulse1",
				"misc-latch",
				"sw-exception",
				"ce0",
				"ce1",
				"ce2",
				"ce3",
				"ce4",
				"ce5",
				"ce6",
				"ce7",
				"ce8",
				"ce9",
				"ce10",
				"ce11",
				"host2wbm-desc-feed",
				"host2reo-re-injection",
				"host2reo-command",
				"host2rxdma-monitor-ring3",
				"host2rxdma-monitor-ring2",
				"host2rxdma-monitor-ring1",
				"reo2ost-exception",
				"wbm2host-rx-release",
				"reo2host-status",
				"reo2host-destination-ring4",
				"reo2host-destination-ring3",
				"reo2host-destination-ring2",
				"reo2host-destination-ring1",
				"rxdma2host-monitor-destination-mac3",
				"rxdma2host-monitor-destination-mac2",
				"rxdma2host-monitor-destination-mac1",
				"ppdu-end-interrupts-mac3",
				"ppdu-end-interrupts-mac2",
				"ppdu-end-interrupts-mac1",
				"rxdma2host-monitor-status-ring-mac3",
				"rxdma2host-monitor-status-ring-mac2",
				"rxdma2host-monitor-status-ring-mac1",
				"host2rxdma-host-buf-ring-mac3",
				"host2rxdma-host-buf-ring-mac2",
				"host2rxdma-host-buf-ring-mac1",
				"rxdma2host-destination-ring-mac3",
				"rxdma2host-destination-ring-mac2",
				"rxdma2host-destination-ring-mac1",
				"host2tcl-input-ring4",
				"host2tcl-input-ring3",
				"host2tcl-input-ring2",
				"host2tcl-input-ring1",
				"wbm2host-tx-completions-ring4",
				"wbm2host-tx-completions-ring3",
				"wbm2host-tx-completions-ring2",
				"wbm2host-tx-completions-ring1",
				"tcl2host-status-ring";

			qcom,pta-num = <0>;
			qcom,coex-mode = <0x2>;
			qcom,bt-active-time = <0x12>;
			qcom,bt-priority-time = <0x0c>;
			qcom,coex-algo = <0x2>;
			qcom,pta-priority = <0x80800505>;
			status = "disabled";
		};

		wifi1: wifi1@f00000 {
			compatible  = "qcom,cnss-qcn9000";
			qcom,wlan-ramdump-dynamic = <0x400000>;
			qrtr_node_id = <0x20>;
			qca,auto-restart;
			interrupt-bmap = <0x100503>;
			status = "disabled";
		};

		wifi2: wifi2@f00000 {
			compatible  = "qcom,cnss-qcn9000";
			qcom,wlan-ramdump-dynamic = <0x400000>;
			qrtr_node_id = <0x21>;
			qca,auto-restart;
			interrupt-bmap = <0x100503>;
			status = "disabled";
		};

		wifi3: wifi3@f00000 {
			compatible  = "qcom,cnss-qcn9000";
			qcom,wlan-ramdump-dynamic = <0x400000>;
			qrtr_node_id = <0x22>;
			qca,auto-restart;
			interrupt-bmap = <0x100503>;
			status = "disabled";
		};

		wifi4: wifi4@f00000 {
			compatible  = "qcom,cnss-qcn9224";
			qcom,wlan-ramdump-dynamic = <0x600000>;
			qca,auto-restart;
			interrupt-bmap = <0x100512>;
#ifdef __IPQ_MEM_PROFILE_512_MB__
			/* qcn9224 tgt-mem-mode=1 layout - 37MB
			 * +=========+==============+=========+
			 * |  Region | Start Offset |   Size  |
			 * +---------+--------------+---------+
			 * | HREMOTE |  0x4CF00000  |   20MB  |
			 * +---------+--------------+---------+
			 * | M3 Dump |  0x4E300000  |   1MB   |
			 * +---------+--------------+---------+
			 * |   ETR   |  0x4E400000  |   1MB   |
			 * +---------+--------------+---------+
			 * |  Caldb  |  0x4E500000  |   8MB   |
			 * +---------+--------------+---------+
			 * |Pageable |  0x4ED00000  |   7MB   |
			 * +==================================+
			 */
			base-addr = <0x4CF00000>;
			m3-dump-addr = <0x4E300000>;
			etr-addr = <0x4E400000>;
			caldb-addr = <0x4E500000>;
			pageable-addr = <0x4ED00000>;
			hremote-size = <0x1400000>;
			pageable-size = <0x700000>;
			tgt-mem-mode = <0x1>;
#else
			/* qcn9224 tgt-mem-mode=0 layout - 50MB
			 * +=========+==============+=========+
			 * |  Region | Start Offset |   Size  |
			 * +---------+--------------+---------+
			 * | HREMOTE |  0x4DD00000  |   28MB  |
			 * +---------+--------------+---------+
			 * | M3 Dump |  0x4F900000  |   1MB   |
			 * +---------+--------------+---------+
			 * |   ETR   |  0x4FA00000  |   1MB   |
			 * +---------+--------------+---------+
			 * |  Caldb  |  0x4FB00000  |   8MB   |
			 * +---------+--------------+---------+
			 * |Pageable |  0x50300000  |  12MB   |
			 * +==================================+
			 */
			base-addr = <0x4DD00000>;
			m3-dump-addr = <0x4F900000>;
			etr-addr = <0x4FA00000>;
			caldb-addr = <0x4FB00000>;
			pageable-addr = <0x50300000>;
			hremote-size = <0x1C00000>;
			pageable-size = <0xC00000>;
			tgt-mem-mode = <0x0>;
#endif
			caldb-size = <0x800000>;
			qca,extended-intc;
			interrupts-extended =
				<&qcn9224_in0 5 0>,
				<&qcn9224_in0 6 0>,
				<&qcn9224_in0 7 0>,
				<&qcn9224_in0 8 0>,
				<&qcn9224_in0 9 0>,
				<&qcn9224_in0 10 0>,
				<&qcn9224_in0 11 0>,
				<&qcn9224_in0 12 0>,
				<&qcn9224_in0 13 0>,
				<&qcn9224_in0 14 0>,
				<&qcn9224_in0 15 0>,
				<&qcn9224_in0 16 0>,
				<&qcn9224_in0 17 0>,
				<&qcn9224_in0 18 0>,
				<&qcn9224_in0 19 0>,
				<&qcn9224_in0 20 0>,
				<&qcn9224_in0 49 0>,
				<&qcn9224_in0 48 0>,
				<&qcn9224_in0 47 0>,
				<&qcn9224_in0 46 0>,
				<&qcn9224_in0 45 0>,
				<&qcn9224_in0 44 0>,
				<&qcn9224_in0 43 0>,
				<&qcn9224_in0 42 0>,
				<&qcn9224_in0 50 0>,
				<&qcn9224_in0 52 0>,
				<&qcn9224_in0 51 0>,
				<&qcn9224_in0 30 0>,
				<&qcn9224_in0 29 0>,
				<&qcn9224_in0 28 0>,
				<&qcn9224_in0 27 0>,
				<&qcn9224_in0 26 0>,
				<&qcn9224_in0 25 0>,
				<&qcn9224_in0 31 0>,
				<&qcn9224_in0 80 0>,
				<&qcn9224_in0 71 0>,
				<&qcn9224_in0 96 0>,
				<&qcn9224_in0 97 0>,
				<&qcn9224_in0 67 0>,
				<&qcn9224_in0 100 0>,
				<&qcn9224_in0 99 0>,
				<&qcn9224_in0 68 0>,
				<&qcn9224_in0 69 0>,
				<&qcn9224_in0 121 0>,
				<&qcn9224_in0 119 0>,
				<&qcn9224_in0 122 0>,
				<&qcn9224_in0 120 0>,
				<&qcn9224_in0 116 0>,
				<&qcn9224_in0 113 0>,
				<&qcn9224_in0 115 0>,
				<&qcn9224_in0 112 0>,
				<&qcn9224_in0 114 0>,
				<&qcn9224_in0 111 0>,
				<&qcn9224_in0 110 0>,
				<&qcn9224_in0 109 0>,
				<&qcn9224_in0 108 0>,
				<&qcn9224_in0 39 0>,
				<&qcn9224_in0 38 0>,
				<&qcn9224_in0 37 0>,
				<&qcn9224_in0 36 0>,
				<&qcn9224_in0 35 0>,
				<&qcn9224_in0 34 0>,
				<&qcn9224_in0 33 0>,
				<&qcn9224_in0 41 0>,
				<&qcn9224_in0 40 0>,
				<&qcn9224_in0 32 0>,
				<&qcn9224_in0 24 0>,
				<&qcn9224_in0 23 0>,
				<&qcn9224_in0 22 0>,
				<&qcn9224_in0 21 0>,
				<&qcn9224_in0 66 0>,
				<&qcn9224_in0 78 0>,
				<&qcn9224_in0 117 0>,
				<&qcn9224_in0 118 0>,
				<&qcn9224_in0 61 0>,
				<&qcn9224_in0 60 0>,
				<&qcn9224_in0 57 0>,
				<&qcn9224_in0 56 0>,
				<&qcn9224_in0 63 0>,
				<&qcn9224_in0 62 0>,
				<&qcn9224_in0 59 0>,
				<&qcn9224_in0 58 0>,
				<&qcn9224_in0 65 0>,
				<&qcn9224_in0 83 0>,
				<&qcn9224_in0 75 0>,
				<&qcn9224_in0 82 0>,
				<&qcn9224_in0 81 0>,
				<&qcn9224_in0 74 0>,
				<&qcn9224_in0 73 0>,
				<&qcn9224_in0 72 0>,
				<&qcn9224_in0 98 0>,
				<&qcn9224_in0 107 0>,
				<&qcn9224_in0 106 0>,
				<&qcn9224_in0 105 0>,
				<&qcn9224_in0 104 0>,
				<&qcn9224_in0 103 0>,
				<&qcn9224_in0 102 0>,
				<&qcn9224_in0 101 0>,
				<&qcn9224_in0 76 0>,
				<&qcn9224_in0 77 0>,
				<&qcn9224_in0 143 0>,
				<&qcn9224_in0 142 0>,
				<&qcn9224_in0 141 0>,
				<&intc GIC_SPI 75 IRQ_TYPE_LEVEL_HIGH>;

			interrupt-names = "ce0",
				"ce1",
				"ce2",
				"ce3",
				"ce4",
				"ce5",
				"ce6",
				"ce7",
				"ce8",
				"ce9",
				"ce10",
				"ce11",
				"ce12",
				"ce13",
				"ce14",
				"ce15",
				"reo2sw8_intr2",
				"reo2sw7_intr2",
				"reo2sw6_intr2",
				"reo2sw5_intr2",
				"reo2sw4_intr2",
				"reo2sw3_intr2",
				"reo2sw2_intr2",
				"reo2sw1_intr2",
				"reo2sw0_intr2",
				"reo2sw8_intr",
				"reo2sw7_intr",
				"reo2sw6_inrr",
				"reo2sw5_intr",
				"reo2sw4_intr",
				"reo2sw3_intr",
				"reo2sw2_intr",
				"reo2sw1_intr",
				"reo2sw0_intr",
				"reo2status_intr2",
				"reo_status",
				"reo2rxdma_out_2",
				"reo2rxdma_out_1",
				"reo_cmd",
				"sw2reo6",
				"sw2reo5",
				"sw2reo1",
				"sw2reo",
				"rxdma2reo_mlo_0_dst_ring1",
				"rxdma2reo_mlo_0_dst_ring0",
				"rxdma2reo_mlo_1_dst_ring1",
				"rxdma2reo_mlo_1_dst_ring0",
				"rxdma2reo_dst_ring1",
				"rxdma2reo_dst_ring0",
				"rxdma2sw_dst_ring1",
				"rxdma2sw_dst_ring0",
				"rxdma2release_dst_ring1",
				"rxdma2release_dst_ring0",
				"sw2rxdma_2_src_ring",
				"sw2rxdma_1_src_ring",
				"sw2rxdma_0",
				"wbm2sw6_release2",
				"wbm2sw5_release2",
				"wbm2sw4_release2",
				"wbm2sw3_release2",
				"wbm2sw2_release2",
				"wbm2sw1_release2",
				"wbm2sw0_release2",
				"wbm2sw6_release",
				"wbm2sw5_release",
				"wbm2sw4_release",
				"wbm2sw3_release",
				"wbm2sw2_release",
				"wbm2sw1_release",
				"wbm2sw0_release",
				"wbm2sw_link",
				"wbm_error_release",
				"sw2txmon_src_ring",
				"sw2rxmon_src_ring",
				"txmon2sw_p1_intr1",
				"txmon2sw_p1_intr0",
				"txmon2sw_p0_dest1",
				"txmon2sw_p0_dest0",
				"rxmon2sw_p1_intr1",
				"rxmon2sw_p1_intr0",
				"rxmon2sw_p0_dest1",
				"rxmon2sw_p0_dest0",
				"sw_release",
				"sw2tcl_credit2",
				"sw2tcl_credit",
				"sw2tcl4",
				"sw2tcl5",
				"sw2tcl3",
				"sw2tcl2",
				"sw2tcl1",
				"sw2wbm1",
				"misc_8",
				"misc_7",
				"misc_6",
				"misc_5",
				"misc_4",
				"misc_3",
				"misc_2",
				"misc_1",
				"misc_0",
				"mhi2",
				"mhi1",
				"mhi0",
				"inta";

			status = "disabled";
		};

		wifi5: wifi5@f00000 {
			compatible  = "qcom,cnss-qcn9224";
			qcom,wlan-ramdump-dynamic = <0x600000>;
			qca,auto-restart;
			interrupt-bmap = <0x100512>;
#ifdef __IPQ_MEM_PROFILE_512_MB__
			/* qcn9224 tgt-mem-mode=1 layout - 37MB
			 * +=========+==============+=========+
			 * |  Region | Start Offset |   Size  |
			 * +---------+--------------+---------+
			 * | HREMOTE |  0x4F400000  |   20MB  |
			 * +---------+--------------+---------+
			 * | M3 Dump |  0x50800000  |   1MB   |
			 * +---------+--------------+---------+
			 * |   ETR   |  0x50900000  |   1MB   |
			 * +---------+--------------+---------+
			 * |  Caldb  |  0x50A00000  |   8MB   |
			 * +---------+--------------+---------+
			 * |Pageable |  0x51200000  |   7MB   |
			 * +==================================+
			 */
			base-addr = <0x4F400000>;
			m3-dump-addr = <0x50800000>;
			etr-addr = <0x50900000>;
			caldb-addr = <0x50A00000>;
			pageable-addr = <0x51200000>;
			hremote-size = <0x1400000>;
			pageable-size = <0x700000>;
			tgt-mem-mode = <0x1>;
#else
			/* qcn9224 tgt-mem-mode=0 layout - 50MB
			 * +=========+==============+=========+
			 * |  Region | Start Offset |   Size  |
			 * +---------+--------------+---------+
			 * | HREMOTE |  0x50F00000  |   28MB  |
			 * +---------+--------------+---------+
			 * | M3 Dump |  0x52B00000  |   1MB   |
			 * +---------+--------------+---------+
			 * |   ETR   |  0x52C00000  |   1MB   |
			 * +---------+--------------+---------+
			 * |  Caldb  |  0x52D00000  |   8MB   |
			 * +---------+--------------+---------+
			 * |Pageable |  0x53500000  |  12MB   |
			 * +==================================+
			 */
			base-addr = <0x50F00000>;
			m3-dump-addr = <0x52B00000>;
			etr-addr = <0x52C00000>;
			caldb-addr = <0x52D00000>;
			pageable-addr = <0x53500000>;
			hremote-size = <0x1C00000>;
			pageable-size = <0xC00000>;
			tgt-mem-mode = <0x0>;
#endif
			caldb-size = <0x800000>;
			qca,extended-intc;
			interrupts-extended =
				<&qcn9224_in1 5 0>,
				<&qcn9224_in1 6 0>,
				<&qcn9224_in1 7 0>,
				<&qcn9224_in1 8 0>,
				<&qcn9224_in1 9 0>,
				<&qcn9224_in1 10 0>,
				<&qcn9224_in1 11 0>,
				<&qcn9224_in1 12 0>,
				<&qcn9224_in1 13 0>,
				<&qcn9224_in1 14 0>,
				<&qcn9224_in1 15 0>,
				<&qcn9224_in1 16 0>,
				<&qcn9224_in1 17 0>,
				<&qcn9224_in1 18 0>,
				<&qcn9224_in1 19 0>,
				<&qcn9224_in1 20 0>,
				<&qcn9224_in1 49 0>,
				<&qcn9224_in1 48 0>,
				<&qcn9224_in1 47 0>,
				<&qcn9224_in1 46 0>,
				<&qcn9224_in1 45 0>,
				<&qcn9224_in1 44 0>,
				<&qcn9224_in1 43 0>,
				<&qcn9224_in1 42 0>,
				<&qcn9224_in1 50 0>,
				<&qcn9224_in1 52 0>,
				<&qcn9224_in1 51 0>,
				<&qcn9224_in1 30 0>,
				<&qcn9224_in1 29 0>,
				<&qcn9224_in1 28 0>,
				<&qcn9224_in1 27 0>,
				<&qcn9224_in1 26 0>,
				<&qcn9224_in1 25 0>,
				<&qcn9224_in1 31 0>,
				<&qcn9224_in1 80 0>,
				<&qcn9224_in1 71 0>,
				<&qcn9224_in1 96 0>,
				<&qcn9224_in1 97 0>,
				<&qcn9224_in1 67 0>,
				<&qcn9224_in1 100 0>,
				<&qcn9224_in1 99 0>,
				<&qcn9224_in1 68 0>,
				<&qcn9224_in1 69 0>,
				<&qcn9224_in1 121 0>,
				<&qcn9224_in1 119 0>,
				<&qcn9224_in1 122 0>,
				<&qcn9224_in1 120 0>,
				<&qcn9224_in1 116 0>,
				<&qcn9224_in1 113 0>,
				<&qcn9224_in1 115 0>,
				<&qcn9224_in1 112 0>,
				<&qcn9224_in1 114 0>,
				<&qcn9224_in1 111 0>,
				<&qcn9224_in1 110 0>,
				<&qcn9224_in1 109 0>,
				<&qcn9224_in1 108 0>,
				<&qcn9224_in1 39 0>,
				<&qcn9224_in1 38 0>,
				<&qcn9224_in1 37 0>,
				<&qcn9224_in1 36 0>,
				<&qcn9224_in1 35 0>,
				<&qcn9224_in1 34 0>,
				<&qcn9224_in1 33 0>,
				<&qcn9224_in1 41 0>,
				<&qcn9224_in1 40 0>,
				<&qcn9224_in1 32 0>,
				<&qcn9224_in1 24 0>,
				<&qcn9224_in1 23 0>,
				<&qcn9224_in1 22 0>,
				<&qcn9224_in1 21 0>,
				<&qcn9224_in1 66 0>,
				<&qcn9224_in1 78 0>,
				<&qcn9224_in1 117 0>,
				<&qcn9224_in1 118 0>,
				<&qcn9224_in1 61 0>,
				<&qcn9224_in1 60 0>,
				<&qcn9224_in1 57 0>,
				<&qcn9224_in1 56 0>,
				<&qcn9224_in1 63 0>,
				<&qcn9224_in1 62 0>,
				<&qcn9224_in1 59 0>,
				<&qcn9224_in1 58 0>,
				<&qcn9224_in1 65 0>,
				<&qcn9224_in1 83 0>,
				<&qcn9224_in1 75 0>,
				<&qcn9224_in1 82 0>,
				<&qcn9224_in1 81 0>,
				<&qcn9224_in1 74 0>,
				<&qcn9224_in1 73 0>,
				<&qcn9224_in1 72 0>,
				<&qcn9224_in1 98 0>,
				<&qcn9224_in1 107 0>,
				<&qcn9224_in1 106 0>,
				<&qcn9224_in1 105 0>,
				<&qcn9224_in1 104 0>,
				<&qcn9224_in1 103 0>,
				<&qcn9224_in1 102 0>,
				<&qcn9224_in1 101 0>,
				<&qcn9224_in1 76 0>,
				<&qcn9224_in1 77 0>,
				<&qcn9224_in1 143 0>,
				<&qcn9224_in1 142 0>,
				<&qcn9224_in1 141 0>,
				<&intc GIC_SPI 35 IRQ_TYPE_LEVEL_HIGH>;

			interrupt-names = "ce0",
				"ce1",
				"ce2",
				"ce3",
				"ce4",
				"ce5",
				"ce6",
				"ce7",
				"ce8",
				"ce9",
				"ce10",
				"ce11",
				"ce12",
				"ce13",
				"ce14",
				"ce15",
				"reo2sw8_intr2",
				"reo2sw7_intr2",
				"reo2sw6_intr2",
				"reo2sw5_intr2",
				"reo2sw4_intr2",
				"reo2sw3_intr2",
				"reo2sw2_intr2",
				"reo2sw1_intr2",
				"reo2sw0_intr2",
				"reo2sw8_intr",
				"reo2sw7_intr",
				"reo2sw6_inrr",
				"reo2sw5_intr",
				"reo2sw4_intr",
				"reo2sw3_intr",
				"reo2sw2_intr",
				"reo2sw1_intr",
				"reo2sw0_intr",
				"reo2status_intr2",
				"reo_status",
				"reo2rxdma_out_2",
				"reo2rxdma_out_1",
				"reo_cmd",
				"sw2reo6",
				"sw2reo5",
				"sw2reo1",
				"sw2reo",
				"rxdma2reo_mlo_0_dst_ring1",
				"rxdma2reo_mlo_0_dst_ring0",
				"rxdma2reo_mlo_1_dst_ring1",
				"rxdma2reo_mlo_1_dst_ring0",
				"rxdma2reo_dst_ring1",
				"rxdma2reo_dst_ring0",
				"rxdma2sw_dst_ring1",
				"rxdma2sw_dst_ring0",
				"rxdma2release_dst_ring1",
				"rxdma2release_dst_ring0",
				"sw2rxdma_2_src_ring",
				"sw2rxdma_1_src_ring",
				"sw2rxdma_0",
				"wbm2sw6_release2",
				"wbm2sw5_release2",
				"wbm2sw4_release2",
				"wbm2sw3_release2",
				"wbm2sw2_release2",
				"wbm2sw1_release2",
				"wbm2sw0_release2",
				"wbm2sw6_release",
				"wbm2sw5_release",
				"wbm2sw4_release",
				"wbm2sw3_release",
				"wbm2sw2_release",
				"wbm2sw1_release",
				"wbm2sw0_release",
				"wbm2sw_link",
				"wbm_error_release",
				"sw2txmon_src_ring",
				"sw2rxmon_src_ring",
				"txmon2sw_p1_intr1",
				"txmon2sw_p1_intr0",
				"txmon2sw_p0_dest1",
				"txmon2sw_p0_dest0",
				"rxmon2sw_p1_intr1",
				"rxmon2sw_p1_intr0",
				"rxmon2sw_p0_dest1",
				"rxmon2sw_p0_dest0",
				"sw_release",
				"sw2tcl_credit2",
				"sw2tcl_credit",
				"sw2tcl4",
				"sw2tcl5",
				"sw2tcl3",
				"sw2tcl2",
				"sw2tcl1",
				"sw2wbm1",
				"misc_8",
				"misc_7",
				"misc_6",
				"misc_5",
				"misc_4",
				"misc_3",
				"misc_2",
				"misc_1",
				"misc_0",
				"mhi2",
				"mhi1",
				"mhi0",
				"inta";

			status = "disabled";
		};

		wifi6: wifi6@f00000 {
			compatible  = "qcom,cnss-qcn9224";
			qcom,wlan-ramdump-dynamic = <0x600000>;
			qca,auto-restart;
			interrupt-bmap = <0x100512>;
#ifdef __IPQ_MEM_PROFILE_512_MB__
			/* qcn9224 tgt-mem-mode=1 layout - 37MB
			 * +=========+==============+=========+
			 * |  Region | Start Offset |   Size  |
			 * +---------+--------------+---------+
			 * | HREMOTE |  0x51900000  |   20MB  |
			 * +---------+--------------+---------+
			 * | M3 Dump |  0x52D00000  |   1MB   |
			 * +---------+--------------+---------+
			 * |   ETR   |  0x52E00000  |   1MB   |
			 * +---------+--------------+---------+
			 * |  Caldb  |  0x52F00000  |   8MB   |
			 * +---------+--------------+---------+
			 * |Pageable |  0x53700000  |   7MB   |
			 * +==================================+
			 */
			base-addr = <0x51900000>;
			m3-dump-addr = <0x52D00000>;
			etr-addr = <0x52E00000>;
			caldb-addr = <0x52F00000>;
			pageable-addr = <0x53700000>;
			hremote-size = <0x1400000>;
			pageable-size = <0x700000>;
			tgt-mem-mode = <0x1>;
#else
			/* qcn9224 tgt-mem-mode=0 layout - 50MB
			 * +=========+==============+=========+
			 * |  Region | Start Offset |   Size  |
			 * +---------+--------------+---------+
			 * | HREMOTE |  0x54100000  |   28MB  |
			 * +---------+--------------+---------+
			 * | M3 Dump |  0x55D00000  |   1MB   |
			 * +---------+--------------+---------+
			 * |   ETR   |  0x55E00000  |   1MB   |
			 * +---------+--------------+---------+
			 * |  Caldb  |  0x55F00000  |   8MB   |
			 * +---------+--------------+---------+
			 * |Pageable |  0x56700000  |  12MB   |
			 * +==================================+
			 */
			base-addr = <0x54100000>;
			m3-dump-addr = <0x55D00000>;
			etr-addr = <0x55E00000>;
			caldb-addr = <0x55F00000>;
			pageable-addr = <0x56700000>;
			hremote-size = <0x1C00000>;
			pageable-size = <0xC00000>;
			tgt-mem-mode = <0x0>;
#endif
			caldb-size = <0x800000>;
			qca,extended-intc;
			interrupts-extended =
				<&qcn9224_in2 5 0>,
				<&qcn9224_in2 6 0>,
				<&qcn9224_in2 7 0>,
				<&qcn9224_in2 8 0>,
				<&qcn9224_in2 9 0>,
				<&qcn9224_in2 10 0>,
				<&qcn9224_in2 11 0>,
				<&qcn9224_in2 12 0>,
				<&qcn9224_in2 13 0>,
				<&qcn9224_in2 14 0>,
				<&qcn9224_in2 15 0>,
				<&qcn9224_in2 16 0>,
				<&qcn9224_in2 17 0>,
				<&qcn9224_in2 18 0>,
				<&qcn9224_in2 19 0>,
				<&qcn9224_in2 20 0>,
				<&qcn9224_in2 49 0>,
				<&qcn9224_in2 48 0>,
				<&qcn9224_in2 47 0>,
				<&qcn9224_in2 46 0>,
				<&qcn9224_in2 45 0>,
				<&qcn9224_in2 44 0>,
				<&qcn9224_in2 43 0>,
				<&qcn9224_in2 42 0>,
				<&qcn9224_in2 50 0>,
				<&qcn9224_in2 52 0>,
				<&qcn9224_in2 51 0>,
				<&qcn9224_in2 30 0>,
				<&qcn9224_in2 29 0>,
				<&qcn9224_in2 28 0>,
				<&qcn9224_in2 27 0>,
				<&qcn9224_in2 26 0>,
				<&qcn9224_in2 25 0>,
				<&qcn9224_in2 31 0>,
				<&qcn9224_in2 80 0>,
				<&qcn9224_in2 71 0>,
				<&qcn9224_in2 96 0>,
				<&qcn9224_in2 97 0>,
				<&qcn9224_in2 67 0>,
				<&qcn9224_in2 100 0>,
				<&qcn9224_in2 99 0>,
				<&qcn9224_in2 68 0>,
				<&qcn9224_in2 69 0>,
				<&qcn9224_in2 121 0>,
				<&qcn9224_in2 119 0>,
				<&qcn9224_in2 122 0>,
				<&qcn9224_in2 120 0>,
				<&qcn9224_in2 116 0>,
				<&qcn9224_in2 113 0>,
				<&qcn9224_in2 115 0>,
				<&qcn9224_in2 112 0>,
				<&qcn9224_in2 114 0>,
				<&qcn9224_in2 111 0>,
				<&qcn9224_in2 110 0>,
				<&qcn9224_in2 109 0>,
				<&qcn9224_in2 108 0>,
				<&qcn9224_in2 39 0>,
				<&qcn9224_in2 38 0>,
				<&qcn9224_in2 37 0>,
				<&qcn9224_in2 36 0>,
				<&qcn9224_in2 35 0>,
				<&qcn9224_in2 34 0>,
				<&qcn9224_in2 33 0>,
				<&qcn9224_in2 41 0>,
				<&qcn9224_in2 40 0>,
				<&qcn9224_in2 32 0>,
				<&qcn9224_in2 24 0>,
				<&qcn9224_in2 23 0>,
				<&qcn9224_in2 22 0>,
				<&qcn9224_in2 21 0>,
				<&qcn9224_in2 66 0>,
				<&qcn9224_in2 78 0>,
				<&qcn9224_in2 117 0>,
				<&qcn9224_in2 118 0>,
				<&qcn9224_in2 61 0>,
				<&qcn9224_in2 60 0>,
				<&qcn9224_in2 57 0>,
				<&qcn9224_in2 56 0>,
				<&qcn9224_in2 63 0>,
				<&qcn9224_in2 62 0>,
				<&qcn9224_in2 59 0>,
				<&qcn9224_in2 58 0>,
				<&qcn9224_in2 65 0>,
				<&qcn9224_in2 83 0>,
				<&qcn9224_in2 75 0>,
				<&qcn9224_in2 82 0>,
				<&qcn9224_in2 81 0>,
				<&qcn9224_in2 74 0>,
				<&qcn9224_in2 73 0>,
				<&qcn9224_in2 72 0>,
				<&qcn9224_in2 98 0>,
				<&qcn9224_in2 107 0>,
				<&qcn9224_in2 106 0>,
				<&qcn9224_in2 105 0>,
				<&qcn9224_in2 104 0>,
				<&qcn9224_in2 103 0>,
				<&qcn9224_in2 102 0>,
				<&qcn9224_in2 101 0>,
				<&qcn9224_in2 76 0>,
				<&qcn9224_in2 77 0>,
				<&qcn9224_in2 143 0>,
				<&qcn9224_in2 142 0>,
				<&qcn9224_in2 141 0>,
				<&intc GIC_SPI 164 IRQ_TYPE_LEVEL_HIGH>;

			interrupt-names = "ce0",
				"ce1",
				"ce2",
				"ce3",
				"ce4",
				"ce5",
				"ce6",
				"ce7",
				"ce8",
				"ce9",
				"ce10",
				"ce11",
				"ce12",
				"ce13",
				"ce14",
				"ce15",
				"reo2sw8_intr2",
				"reo2sw7_intr2",
				"reo2sw6_intr2",
				"reo2sw5_intr2",
				"reo2sw4_intr2",
				"reo2sw3_intr2",
				"reo2sw2_intr2",
				"reo2sw1_intr2",
				"reo2sw0_intr2",
				"reo2sw8_intr",
				"reo2sw7_intr",
				"reo2sw6_inrr",
				"reo2sw5_intr",
				"reo2sw4_intr",
				"reo2sw3_intr",
				"reo2sw2_intr",
				"reo2sw1_intr",
				"reo2sw0_intr",
				"reo2status_intr2",
				"reo_status",
				"reo2rxdma_out_2",
				"reo2rxdma_out_1",
				"reo_cmd",
				"sw2reo6",
				"sw2reo5",
				"sw2reo1",
				"sw2reo",
				"rxdma2reo_mlo_0_dst_ring1",
				"rxdma2reo_mlo_0_dst_ring0",
				"rxdma2reo_mlo_1_dst_ring1",
				"rxdma2reo_mlo_1_dst_ring0",
				"rxdma2reo_dst_ring1",
				"rxdma2reo_dst_ring0",
				"rxdma2sw_dst_ring1",
				"rxdma2sw_dst_ring0",
				"rxdma2release_dst_ring1",
				"rxdma2release_dst_ring0",
				"sw2rxdma_2_src_ring",
				"sw2rxdma_1_src_ring",
				"sw2rxdma_0",
				"wbm2sw6_release2",
				"wbm2sw5_release2",
				"wbm2sw4_release2",
				"wbm2sw3_release2",
				"wbm2sw2_release2",
				"wbm2sw1_release2",
				"wbm2sw0_release2",
				"wbm2sw6_release",
				"wbm2sw5_release",
				"wbm2sw4_release",
				"wbm2sw3_release",
				"wbm2sw2_release",
				"wbm2sw1_release",
				"wbm2sw0_release",
				"wbm2sw_link",
				"wbm_error_release",
				"sw2txmon_src_ring",
				"sw2rxmon_src_ring",
				"txmon2sw_p1_intr1",
				"txmon2sw_p1_intr0",
				"txmon2sw_p0_dest1",
				"txmon2sw_p0_dest0",
				"rxmon2sw_p1_intr1",
				"rxmon2sw_p1_intr0",
				"rxmon2sw_p0_dest1",
				"rxmon2sw_p0_dest0",
				"sw_release",
				"sw2tcl_credit2",
				"sw2tcl_credit",
				"sw2tcl4",
				"sw2tcl5",
				"sw2tcl3",
				"sw2tcl2",
				"sw2tcl1",
				"sw2wbm1",
				"misc_8",
				"misc_7",
				"misc_6",
				"misc_5",
				"misc_4",
				"misc_3",
				"misc_2",
				"misc_1",
				"misc_0",
				"mhi2",
				"mhi1",
				"mhi0",
				"inta";

			status = "disabled";
		};

		wifi7: wifi7@f00000 {
			compatible  = "qcom,cnss-qcn9224";
			qcom,wlan-ramdump-dynamic = <0x600000>;
			qca,auto-restart;
			interrupt-bmap = <0x100512>;
#ifdef __IPQ_MEM_PROFILE_512_MB__
			/* qcn9224 tgt-mem-mode=1 layout - 37MB
			 * +=========+==============+=========+
			 * |  Region | Start Offset |   Size  |
			 * +---------+--------------+---------+
			 * | HREMOTE |  0x53E00000  |   20MB  |
			 * +---------+--------------+---------+
			 * | M3 Dump |  0x55200000  |   1MB   |
			 * +---------+--------------+---------+
			 * |   ETR   |  0x55300000  |   1MB   |
			 * +---------+--------------+---------+
			 * |  Caldb  |  0x55400000  |   8MB   |
			 * +---------+--------------+---------+
			 * |Pageable |  0x55C00000  |   7MB   |
			 * +==================================+
			 */
			base-addr = <0x53E00000>;
			m3-dump-addr = <0x55200000>;
			etr-addr = <0x55300000>;
			caldb-addr = <0x55400000>;
			pageable-addr = <0x55C00000>;
			hremote-size = <0x1400000>;
			pageable-size = <0x700000>;
			tgt-mem-mode = <0x1>;
#else
			/* qcn9224 tgt-mem-mode=0 layout - 50MB
			 * +=========+==============+=========+
			 * |  Region | Start Offset |   Size  |
			 * +---------+--------------+---------+
			 * | HREMOTE |  0x57300000  |   28MB  |
			 * +---------+--------------+---------+
			 * | M3 Dump |  0x58F00000  |   1MB   |
			 * +---------+--------------+---------+
			 * |   ETR   |  0x59000000  |   1MB   |
			 * +---------+--------------+---------+
			 * |  Caldb  |  0x59100000  |   8MB   |
			 * +---------+---------+---------+
			 * |Pageable |  0x59900000  |  12MB   |
			 * +==================================+
			 */
			base-addr = <0x57300000>;
			m3-dump-addr = <0x58F00000>;
			etr-addr = <0x59000000>;
			caldb-addr = <0x59100000>;
			pageable-addr = <0x59900000>;
			hremote-size = <0x1C00000>;
			pageable-size = <0xC00000>;
			tgt-mem-mode = <0x0>;
#endif
			caldb-size = <0x800000>;
			qca,extended-intc;
			interrupts-extended =
				<&qcn9224_in3 5 0>,
				<&qcn9224_in3 6 0>,
				<&qcn9224_in3 7 0>,
				<&qcn9224_in3 8 0>,
				<&qcn9224_in3 9 0>,
				<&qcn9224_in3 10 0>,
				<&qcn9224_in3 11 0>,
				<&qcn9224_in3 12 0>,
				<&qcn9224_in3 13 0>,
				<&qcn9224_in3 14 0>,
				<&qcn9224_in3 15 0>,
				<&qcn9224_in3 16 0>,
				<&qcn9224_in3 17 0>,
				<&qcn9224_in3 18 0>,
				<&qcn9224_in3 19 0>,
				<&qcn9224_in3 20 0>,
				<&qcn9224_in3 49 0>,
				<&qcn9224_in3 48 0>,
				<&qcn9224_in3 47 0>,
				<&qcn9224_in3 46 0>,
				<&qcn9224_in3 45 0>,
				<&qcn9224_in3 44 0>,
				<&qcn9224_in3 43 0>,
				<&qcn9224_in3 42 0>,
				<&qcn9224_in3 50 0>,
				<&qcn9224_in3 52 0>,
				<&qcn9224_in3 51 0>,
				<&qcn9224_in3 30 0>,
				<&qcn9224_in3 29 0>,
				<&qcn9224_in3 28 0>,
				<&qcn9224_in3 27 0>,
				<&qcn9224_in3 26 0>,
				<&qcn9224_in3 25 0>,
				<&qcn9224_in3 31 0>,
				<&qcn9224_in3 80 0>,
				<&qcn9224_in3 71 0>,
				<&qcn9224_in3 96 0>,
				<&qcn9224_in3 97 0>,
				<&qcn9224_in3 67 0>,
				<&qcn9224_in3 100 0>,
				<&qcn9224_in3 99 0>,
				<&qcn9224_in3 68 0>,
				<&qcn9224_in3 69 0>,
				<&qcn9224_in3 121 0>,
				<&qcn9224_in3 119 0>,
				<&qcn9224_in3 122 0>,
				<&qcn9224_in3 120 0>,
				<&qcn9224_in3 116 0>,
				<&qcn9224_in3 113 0>,
				<&qcn9224_in3 115 0>,
				<&qcn9224_in3 112 0>,
				<&qcn9224_in3 114 0>,
				<&qcn9224_in3 111 0>,
				<&qcn9224_in3 110 0>,
				<&qcn9224_in3 109 0>,
				<&qcn9224_in3 108 0>,
				<&qcn9224_in3 39 0>,
				<&qcn9224_in3 38 0>,
				<&qcn9224_in3 37 0>,
				<&qcn9224_in3 36 0>,
				<&qcn9224_in3 35 0>,
				<&qcn9224_in3 34 0>,
				<&qcn9224_in3 33 0>,
				<&qcn9224_in3 41 0>,
				<&qcn9224_in3 40 0>,
				<&qcn9224_in3 32 0>,
				<&qcn9224_in3 24 0>,
				<&qcn9224_in3 23 0>,
				<&qcn9224_in3 22 0>,
				<&qcn9224_in3 21 0>,
				<&qcn9224_in3 66 0>,
				<&qcn9224_in3 78 0>,
				<&qcn9224_in3 117 0>,
				<&qcn9224_in3 118 0>,
				<&qcn9224_in3 61 0>,
				<&qcn9224_in3 60 0>,
				<&qcn9224_in3 57 0>,
				<&qcn9224_in3 56 0>,
				<&qcn9224_in3 63 0>,
				<&qcn9224_in3 62 0>,
				<&qcn9224_in3 59 0>,
				<&qcn9224_in3 58 0>,
				<&qcn9224_in3 65 0>,
				<&qcn9224_in3 83 0>,
				<&qcn9224_in3 75 0>,
				<&qcn9224_in3 82 0>,
				<&qcn9224_in3 81 0>,
				<&qcn9224_in3 74 0>,
				<&qcn9224_in3 73 0>,
				<&qcn9224_in3 72 0>,
				<&qcn9224_in3 98 0>,
				<&qcn9224_in3 107 0>,
				<&qcn9224_in3 106 0>,
				<&qcn9224_in3 105 0>,
				<&qcn9224_in3 104 0>,
				<&qcn9224_in3 103 0>,
				<&qcn9224_in3 102 0>,
				<&qcn9224_in3 101 0>,
				<&qcn9224_in3 76 0>,
				<&qcn9224_in3 77 0>,
				<&qcn9224_in3 143 0>,
				<&qcn9224_in3 142 0>,
				<&qcn9224_in3 141 0>,
				<&intc GIC_SPI 189 IRQ_TYPE_LEVEL_HIGH>;

			interrupt-names = "ce0",
				"ce1",
				"ce2",
				"ce3",
				"ce4",
				"ce5",
				"ce6",
				"ce7",
				"ce8",
				"ce9",
				"ce10",
				"ce11",
				"ce12",
				"ce13",
				"ce14",
				"ce15",
				"reo2sw8_intr2",
				"reo2sw7_intr2",
				"reo2sw6_intr2",
				"reo2sw5_intr2",
				"reo2sw4_intr2",
				"reo2sw3_intr2",
				"reo2sw2_intr2",
				"reo2sw1_intr2",
				"reo2sw0_intr2",
				"reo2sw8_intr",
				"reo2sw7_intr",
				"reo2sw6_inrr",
				"reo2sw5_intr",
				"reo2sw4_intr",
				"reo2sw3_intr",
				"reor",
				"reo2sw1_intr",
				"reo2sw0_intr",
				"reo2status_intr2",
				"reo_status",
				"reo2rxdma_out_2",
				"reo2rxdma_out_1",
				"reo_cmd",
				"sw2reo6",
				"sw2reo5",
				"sw2reo1",
				"sw2reo",
				"rxdma2reo_mlo_0_dst_ring1",
				"rxdma2reo_mlo_0_dst_ring0",
				"rxdma2reo_mlo_1_dst_ring1",
				"rxdma2reo_mlo_1_dst_ring0",
				"rxdma2reo_dst_ring1",
				"rxdma2reo_dst_ring0",
				"rxdma2sw_dst_ring1",
				"rxdma2sw_dst_ring0",
				"rxdma2release_dst_ring1",
				"rxdma2release_dst_ring0",
				"sw2rxdma_2_src_ring",
				"sw2rxdma_1_src_ring",
				"sw2rxdma_0",
				"wbm2sw6_release2",
				"wbm2sw5_release2",
				"wbm2sw4_release2",
				"wbm2sw3_release2",
				"wbm2sw2_release2",
				"wbm2sw1_release2",
				"wbm2sw0_release2",
				"wbm2sw6_release",
				"wbm2sw5_release",
				"wbm2sw4_release",
				"wbm2sw3_release",
				"wbm2sw2_release",
				"wbm2sw1_release",
				"wbm2sw0_release",
				"wbm2sw_link",
				"wbm_error_release",
				"sw2txmon_src_ring",
				"sw2rxmon_src_ring",
				"txmon2sw_p1_intr1",
				"txmon2sw_p1_intr0",
				"txmon2sw_p0_dest1",
				"txmon2sw_p0_dest0",
				"rxmon2sw_p1_intr1",
				"rxmon2sw_p1_intr0",
				"rxmon2sw_p0_dest1",
				"rxmon2sw_p0_dest0",
				"sw_release",
				"sw2tcl_credit2",
				"sw2tcl_credit",
				"sw2tcl4",
				"sw2tcl5",
				"sw2tcl3",
				"sw2tcl2",
				"sw2tcl1",
				"sw2wbm1",
				"misc_8",
				"misc_7",
				"misc_6",
				"misc_5",
				"misc_4",
				"misc_3",
				"misc_2",
				"misc_1",
				"misc_0",
				"mhi2",
				"mhi1",
				"mhi0",
				"inta";

			status = "disabled";
		};

		qusb_phy_0: phy@7b000 {
			compatible = "qcom,ipq9574-qusb2-phy";
			reg = <0x07b000 0x180>;
			#phy-cells = <0>;

			clocks = <&gcc GCC_USB0_PHY_CFG_AHB_CLK>,
				<&xo>;
			clock-names = "cfg_ahb", "ref";

			resets = <&gcc GCC_QUSB2_0_PHY_BCR>;
			status = "disabled";
		};

		ssphy_0: phy@7d000 {
			compatible = "qcom,ipq9574-qmp-usb3-phy";
			reg = <0x7d000 0x1c4>;
			#clock-cells = <1>;
			#address-cells = <1>;
			#size-cells = <1>;
			ranges;

			clocks = <&gcc GCC_USB0_AUX_CLK>,
				 <&gcc GCC_USB0_PHY_CFG_AHB_CLK>;
			clock-names = "aux", "cfg_ahb";

			resets =  <&gcc GCC_USB0_PHY_BCR>,
				 <&gcc GCC_USB3PHY_0_PHY_BCR>;
			reset-names = "phy","common";
			status = "disabled";

			usb0_ssphy: phy@7d200 {
				reg = <0x0007d200 0x130>,	/* tx */
				      <0x0007d400 0x200>,	/* rx */
				      <0x0007d800 0x1f8>,	/* pcs  */
				      <0x0007d600 0x044>;	/* pcs misc */
				#phy-cells = <0>;
				clocks = <&gcc GCC_USB0_PIPE_CLK>;
				clock-names = "pipe0";
				clock-output-names = "usb0_pipe_clk";
			};
		};

		usb3: usb3@8a00000 {
			compatible = "qcom,ipq9574-dwc3", "qcom,dwc3";
			reg = <0x8af8800 0x400>;
			#address-cells = <1>;
			#size-cells = <1>;
			ranges;

			clocks = <&gcc GCC_SNOC_USB_CLK>,
				 <&gcc GCC_ANOC_USB_AXI_CLK>,
				 <&gcc GCC_USB0_MASTER_CLK>,
				 <&gcc GCC_USB0_SLEEP_CLK>,
				 <&gcc GCC_USB0_MOCK_UTMI_CLK>;

			clock-names = "sys_noc_axi",
				      "anoc_axi",
				      "master",
				      "sleep",
				      "mock_utmi";

			assigned-clocks = <&gcc GCC_USB0_MASTER_CLK>,
					  <&gcc GCC_USB0_MOCK_UTMI_CLK>;
			assigned-clock-rates = <200000000>,
					       <24000000>;

			resets = <&gcc GCC_USB_BCR>;
			status = "disabled";

			dwc_0: usb@8a00000 {
				compatible = "snps,dwc3";
				reg = <0x8a00000 0xcd00>;
				clocks = <&gcc GCC_USB0_MOCK_UTMI_CLK>;
				clock-names = "ref";
				interrupts = <GIC_SPI 140 IRQ_TYPE_LEVEL_HIGH>;
				phys = <&qusb_phy_0>, <&usb0_ssphy>;
				phy-names = "usb2-phy", "usb3-phy";
				tx-fifo-resize;
				snps,is-utmi-l1-suspend;
				snps,hird-threshold = /bits/ 8 <0x0>;
				snps,dis_u2_susphy_quirk;
				snps,dis_u3_susphy_quirk;
				dr_mode = "host";
			};
		};

		tcsr_mutex: hwlock@1905000 {
			compatible = "qcom,tcsr-mutex";
			reg = <0x01905000 0x20000>;
			#hwlock-cells = <1>;
		};

		msm_imem: qcom,msm-imem@8600000 {
			compatible = "qcom,msm-imem";
			reg = <0x08600000 0x1000>;
			ranges = <0x0 0x08600000 0x1000>;
			#address-cells = <1>;
			#size-cells = <1>;

			tz-log-buf-addr@720 {
				compatible = "qcom,msm-imem-tz-log-buf-addr";
				reg = <0x720 4>;
			};

			restart-reason-buf-addr@7a4 {
				compatible = "qcom,msm-imem-restart-reason-buf-addr";
				reg = <0x7a4 4>;
			};
		};

		tcsr: syscon@1937000 {
			compatible = "qcom,tcsr-ipq9574", "syscon", "simple-mfd";
			reg = <0x01937000 0x21000>;
			#address-cells = <1>;
			#size-cells = <1>;
			ranges = <0x0 0x01937000 0x21000>;

			pwm: pwm@a010 {
				compatible = "qcom,ipq9574-pwm";
				reg = <0xa010 0x20>;
				clocks = <&gcc GCC_ADSS_PWM_CLK>;
				assigned-clocks = <&gcc GCC_ADSS_PWM_CLK>;
				assigned-clock-rates = <100000000>;
				#pwm-cells = <2>;
				status = "disabled";
			};
		};

		sdhc_1: mmc@7804000 {
			compatible = "qcom,ipq9574-sdhci", "qcom,sdhci-msm-v5";
			reg = <0x07804000 0x1000>, <0x07805000 0x1000>,
				<0x7808000 0x2000>;
			reg-names = "hc", "cqhci", "ice";

			interrupts = <GIC_SPI 123 IRQ_TYPE_LEVEL_HIGH>,
				     <GIC_SPI 138 IRQ_TYPE_LEVEL_HIGH>;
			interrupt-names = "hc_irq", "pwr_irq";

			clocks = <&gcc GCC_SDCC1_AHB_CLK>,
				 <&gcc GCC_SDCC1_APPS_CLK>,
				 <&xo>,
				 <&gcc GCC_SDCC1_ICE_CORE_CLK>;
			clock-names = "iface", "core", "xo", "ice";
			non-removable;
			supports-cqe;
			status = "disabled";
		};

		blsp_dma: dma-controller@7884000 {
			compatible = "qcom,bam-v1.7.0";
			reg = <0x07884000 0x2b000>;
			interrupts = <GIC_SPI 238 IRQ_TYPE_LEVEL_HIGH>;
			clocks = <&gcc GCC_BLSP1_AHB_CLK>;
			clock-names = "bam_clk";
			#dma-cells = <1>;
			qcom,ee = <0>;
		};

		blsp1_uart0: serial@78af000 {
			compatible = "qcom,msm-uartdm-v1.4", "qcom,msm-uartdm";
			reg = <0x078af000 0x200>;
			interrupts = <GIC_SPI 107 IRQ_TYPE_LEVEL_HIGH>;
			clocks = <&gcc GCC_BLSP1_UART1_APPS_CLK>,
				 <&gcc GCC_BLSP1_AHB_CLK>;
			clock-names = "core", "iface";
			status = "disabled";
		};

		blsp1_uart1: serial@78b0000 {
			compatible = "qcom,msm-uartdm-v1.4", "qcom,msm-uartdm";
			reg = <0x078b0000 0x200>;
			interrupts = <GIC_SPI 108 IRQ_TYPE_LEVEL_HIGH>;
			clocks = <&gcc GCC_BLSP1_UART2_APPS_CLK>,
				 <&gcc GCC_BLSP1_AHB_CLK>;
			clock-names = "core", "iface";
			status = "disabled";
		};

		blsp1_uart2: serial@78b1000 {
			compatible = "qcom,msm-uartdm-v1.4", "qcom,msm-uartdm";
			reg = <0x078b1000 0x200>;
			interrupts = <GIC_SPI 306 IRQ_TYPE_LEVEL_HIGH>;
			clocks = <&gcc GCC_BLSP1_UART3_APPS_CLK>,
				 <&gcc GCC_BLSP1_AHB_CLK>;
			clock-names = "core", "iface";
			status = "disabled";
			tx-watermark = <0>;
		};

		blsp1_uart3: serial@78b2000 {
			compatible = "qcom,msm-uartdm-v1.4", "qcom,msm-uartdm";
			reg = <0x078b2000 0x200>;
			interrupts = <GIC_SPI 307 IRQ_TYPE_LEVEL_HIGH>;
			clocks = <&gcc GCC_BLSP1_UART4_APPS_CLK>,
				 <&gcc GCC_BLSP1_AHB_CLK>;
			clock-names = "core", "iface";
			status = "disabled";
		};

		blsp1_uart4: serial@78b3000 {
			compatible = "qcom,msm-uartdm-v1.4", "qcom,msm-uartdm";
			reg = <0x078b3000 0x200>;
			interrupts = <GIC_SPI 308 IRQ_TYPE_LEVEL_HIGH>;
			clocks = <&gcc GCC_BLSP1_UART5_APPS_CLK>,
				 <&gcc GCC_BLSP1_AHB_CLK>;
			clock-names = "core", "iface";
			status = "disabled";
		};

		blsp1_uart5: serial@78b4000 {
			compatible = "qcom,msm-uartdm-v1.4", "qcom,msm-uartdm";
			reg = <0x078b4000 0x200>;
			interrupts = <GIC_SPI 309 IRQ_TYPE_LEVEL_HIGH>;
			clocks = <&gcc GCC_BLSP1_UART6_APPS_CLK>,
				 <&gcc GCC_BLSP1_AHB_CLK>;
			clock-names = "core", "iface";
			status = "disabled";
		};

		blsp1_spi0: spi@78b5000 {
			compatible = "qcom,spi-qup-v2.2.1";
			reg = <0x078b5000 0x600>;
			#address-cells = <1>;
			#size-cells = <0>;
			interrupts = <GIC_SPI 95 IRQ_TYPE_LEVEL_HIGH>;
			clocks = <&gcc GCC_BLSP1_QUP1_SPI_APPS_CLK>,
				 <&gcc GCC_BLSP1_AHB_CLK>;
			clock-names = "core", "iface";
			dmas = <&blsp_dma 12>, <&blsp_dma 13>;
			dma-names = "tx", "rx";
			status = "disabled";
		};

		blsp1_i2c1: i2c@78b6000 {
			compatible = "qcom,i2c-qup-v2.2.1";
			reg = <0x078b6000 0x600>;
			#address-cells = <1>;
			#size-cells = <0>;
			interrupts = <GIC_SPI 96 IRQ_TYPE_LEVEL_HIGH>;
			clocks = <&gcc GCC_BLSP1_QUP2_I2C_APPS_CLK>,
				 <&gcc GCC_BLSP1_AHB_CLK>;
			clock-names = "core", "iface";
			dmas = <&blsp_dma 14>, <&blsp_dma 15>;
			dma-names = "tx", "rx";
			status = "disabled";
		};

		blsp1_spi1: spi@78b6000 {
			compatible = "qcom,spi-qup-v2.2.1";
			reg = <0x078b6000 0x600>;
			#address-cells = <1>;
			#size-cells = <0>;
			interrupts = <GIC_SPI 96 IRQ_TYPE_LEVEL_HIGH>;
			clocks = <&gcc GCC_BLSP1_QUP2_SPI_APPS_CLK>,
				 <&gcc GCC_BLSP1_AHB_CLK>;
			clock-names = "core", "iface";
			dmas = <&blsp_dma 14>, <&blsp_dma 15>;
			dma-names = "tx", "rx";
			status = "disabled";
		};

		blsp1_i2c2: i2c@78b7000 {
			compatible = "qcom,i2c-qup-v2.2.1";
			reg = <0x078b7000 0x600>;
			#address-cells = <1>;
			#size-cells = <0>;
			interrupts = <GIC_SPI 97 IRQ_TYPE_LEVEL_HIGH>;
			clocks = <&gcc GCC_BLSP1_QUP3_I2C_APPS_CLK>,
				 <&gcc GCC_BLSP1_AHB_CLK>;
			clock-names = "core", "iface";
			dmas = <&blsp_dma 16>, <&blsp_dma 17>;
			dma-names = "tx", "rx";
			status = "disabled";
		};

		blsp1_spi2: spi@78b7000 {
			compatible = "qcom,spi-qup-v2.2.1";
			reg = <0x078b7000 0x600>;
			#address-cells = <1>;
			#size-cells = <0>;
			interrupts = <GIC_SPI 97 IRQ_TYPE_LEVEL_HIGH>;
			clocks = <&gcc GCC_BLSP1_QUP3_SPI_APPS_CLK>,
				 <&gcc GCC_BLSP1_AHB_CLK>;
			clock-names = "core", "iface";
			dmas = <&blsp_dma 16>, <&blsp_dma 17>;
			dma-names = "tx", "rx";
			status = "disabled";
		};

		blsp1_i2c3: i2c@78b8000 {
			compatible = "qcom,i2c-qup-v2.2.1";
			reg = <0x078b8000 0x600>;
			#address-cells = <1>;
			#size-cells = <0>;
			interrupts = <GIC_SPI 98 IRQ_TYPE_LEVEL_HIGH>;
			clocks = <&gcc GCC_BLSP1_QUP4_I2C_APPS_CLK>,
				 <&gcc GCC_BLSP1_AHB_CLK>;
			clock-names = "core", "iface";
			dmas = <&blsp_dma 18>, <&blsp_dma 19>;
			dma-names = "tx", "rx";
			status = "disabled";
		};

		blsp1_spi3: spi@78b8000 {
			compatible = "qcom,spi-qup-v2.2.1";
			reg = <0x078b8000 0x600>;
			#address-cells = <1>;
			#size-cells = <0>;
			interrupts = <GIC_SPI 98 IRQ_TYPE_LEVEL_HIGH>;
			spi-max-frequency = <50000000>;
			clocks = <&gcc GCC_BLSP1_QUP4_SPI_APPS_CLK>,
				 <&gcc GCC_BLSP1_AHB_CLK>;
			clock-names = "core", "iface";
			dmas = <&blsp_dma 18>, <&blsp_dma 19>;
			dma-names = "tx", "rx";
			status = "disabled";
		};

		blsp1_i2c4: i2c@78b9000 {
			compatible = "qcom,i2c-qup-v2.2.1";
			reg = <0x078b9000 0x600>;
			#address-cells = <1>;
			#size-cells = <0>;
			interrupts = <GIC_SPI 299 IRQ_TYPE_LEVEL_HIGH>;
			clocks = <&gcc GCC_BLSP1_QUP5_I2C_APPS_CLK>,
				 <&gcc GCC_BLSP1_AHB_CLK>;
			clock-names = "core", "iface";
			dmas = <&blsp_dma 20>, <&blsp_dma 21>;
			dma-names = "tx", "rx";
			status = "disabled";
		};

		blsp1_spi4: spi@78b9000 {
			compatible = "qcom,spi-qup-v2.2.1";
			reg = <0x078b9000 0x600>;
			#address-cells = <1>;
			#size-cells = <0>;
			interrupts = <GIC_SPI 299 IRQ_TYPE_LEVEL_HIGH>;
			clocks = <&gcc GCC_BLSP1_QUP5_SPI_APPS_CLK>,
				 <&gcc GCC_BLSP1_AHB_CLK>;
			clock-names = "core", "iface";
			dmas = <&blsp_dma 20>, <&blsp_dma 21>;
			dma-names = "tx", "rx";
			status = "disabled";
		};

		intc: interrupt-controller@b000000 {
			compatible = "qcom,msm-qgic2";
			reg = <0x0b000000 0x1000>,  /* GICD */
			      <0x0b002000 0x1000>,  /* GICC */
			      <0x0b001000 0x1000>,  /* GICH */
			      <0x0b004000 0x1000>;  /* GICV */
			#address-cells = <1>;
			#size-cells = <1>;
			interrupt-controller;
			#interrupt-cells = <3>;
			interrupts = <GIC_PPI 9 IRQ_TYPE_LEVEL_HIGH>;
			ranges = <0 0x0b00c000 0x3000>;

			v2m0: v2m@0 {
				compatible = "arm,gic-v2m-frame";
				reg = <0x00000000 0xffd>;
				msi-controller;
			};

			v2m1: v2m@1000 {
				compatible = "arm,gic-v2m-frame";
				reg = <0x00001000 0xffd>;
				msi-controller;
			};

			v2m2: v2m@2000 {
				compatible = "arm,gic-v2m-frame";
				reg = <0x00002000 0xffd>;
				msi-controller;
			};
		};

		watchdog: watchdog@b017000 {
			compatible = "qcom,apss-wdt-ipq9574", "qcom,kpss-wdt";
			reg = <0x0b017000 0x1000>;
			interrupts = <GIC_SPI 3 IRQ_TYPE_EDGE_RISING>;
			clocks = <&sleep_clk>;
			timeout-sec = <30>;
		};

		apcs_glb: mailbox@b111000 {
			compatible = "qcom,ipq9574-apcs-apps-global",
				     "qcom,ipq6018-apcs-apps-global";
			reg = <0x0b111000 0x1000>;
			#clock-cells = <1>;
			clocks = <&a73pll>, <&xo>, <&gcc_gpll0_out_aux>;
			clock-names = "pll", "xo", "gpll0";
			#mbox-cells = <1>;
		};

		a73pll: clock@b116000 {
			compatible = "qcom,ipq9574-a73pll";
			reg = <0x0b116000 0x40>;
			#clock-cells = <0>;
			clocks = <&xo>;
			clock-names = "xo";
		};

		mdio: mdio@90000 {
			compatible = "qcom,qca-mdio", "qcom,ipq40xx-mdio";
			reg = <0x90000 0x64>, <0x9B000 0x800>;
			reg-names = "ppe", "cmn_blk";
			#address-cells = <1>;
			#size-cells = <1>;
			clocks = <&gcc GCC_MDIO_AHB_CLK>;
			clock-names = "gcc_mdio_ahb_clk";
			status = "disabled";
		};

		ess_instance: ess-instance {
			compatible = "qcom,ess-instance";
			num_devices = <0x1>;
			ess_switch: ess-switch@3a000000 {
				compatible = "qcom,ess-switch-ipq95xx";
				reg = <0x3a000000 0x1000000>;
				switch_access_mode = "local bus";
				switch_cpu_bmp = <0x1>;  /* cpu port bitmap */
				switch_inner_bmp = <0x80>; /*inner port bitmap*/
				bm_tick_mode = <0>; /* bm tick mode */
				tm_tick_mode = <0>; /* tm tick mode */
				clocks = <&gcc GCC_CMN_12GPLL_AHB_CLK>,
					<&gcc GCC_CMN_12GPLL_SYS_CLK>,
					<&gcc GCC_UNIPHY0_AHB_CLK>,
					<&gcc GCC_UNIPHY0_SYS_CLK>,
					<&gcc GCC_UNIPHY1_AHB_CLK>,
					<&gcc GCC_UNIPHY1_SYS_CLK>,
					<&gcc GCC_UNIPHY2_AHB_CLK>,
					<&gcc GCC_UNIPHY2_SYS_CLK>,
					<&gcc GCC_NSSNOC_NSSCC_CLK>,
					<&gcc GCC_NSSCC_CLK>,
					<&gcc GCC_NSSNOC_SNOC_1_CLK>,
					<&gcc GCC_NSSNOC_SNOC_CLK>,
					<&nsscc NSS_CC_PORT1_MAC_CLK>,
					<&nsscc NSS_CC_PORT2_MAC_CLK>,
					<&nsscc NSS_CC_PORT3_MAC_CLK>,
					<&nsscc NSS_CC_PORT4_MAC_CLK>,
					<&nsscc NSS_CC_PORT5_MAC_CLK>,
					<&nsscc NSS_CC_PORT6_MAC_CLK>,
					<&nsscc NSS_CC_PPE_SWITCH_CLK>,
					<&nsscc NSS_CC_PPE_SWITCH_CFG_CLK>,
					<&nsscc NSS_CC_NSSNOC_PPE_CLK>,
					<&nsscc NSS_CC_NSSNOC_PPE_CFG_CLK>,
					<&nsscc NSS_CC_PPE_EDMA_CLK>,
					<&nsscc NSS_CC_PPE_EDMA_CFG_CLK>,
					<&nsscc NSS_CC_PPE_SWITCH_IPE_CLK>,
					<&nsscc NSS_CC_PPE_SWITCH_BTQ_CLK>,
					<&nsscc NSS_CC_PORT1_RX_CLK>,
					<&nsscc NSS_CC_PORT1_TX_CLK>,
					<&nsscc NSS_CC_PORT2_RX_CLK>,
					<&nsscc NSS_CC_PORT2_TX_CLK>,
					<&nsscc NSS_CC_PORT3_RX_CLK>,
					<&nsscc NSS_CC_PORT3_TX_CLK>,
					<&nsscc NSS_CC_PORT4_RX_CLK>,
					<&nsscc NSS_CC_PORT4_TX_CLK>,
					<&nsscc NSS_CC_PORT5_RX_CLK>,
					<&nsscc NSS_CC_PORT5_TX_CLK>,
					<&nsscc NSS_CC_PORT6_RX_CLK>,
					<&nsscc NSS_CC_PORT6_TX_CLK>,
					<&nsscc NSS_CC_UNIPHY_PORT1_RX_CLK>,
					<&nsscc NSS_CC_UNIPHY_PORT1_TX_CLK>,
					<&nsscc NSS_CC_UNIPHY_PORT2_RX_CLK>,
					<&nsscc NSS_CC_UNIPHY_PORT2_TX_CLK>,
					<&nsscc NSS_CC_UNIPHY_PORT3_RX_CLK>,
					<&nsscc NSS_CC_UNIPHY_PORT3_TX_CLK>,
					<&nsscc NSS_CC_UNIPHY_PORT4_RX_CLK>,
					<&nsscc NSS_CC_UNIPHY_PORT4_TX_CLK>,
					<&nsscc NSS_CC_UNIPHY_PORT5_RX_CLK>,
					<&nsscc NSS_CC_UNIPHY_PORT5_TX_CLK>,
					<&nsscc NSS_CC_UNIPHY_PORT6_RX_CLK>,
					<&nsscc NSS_CC_UNIPHY_PORT6_TX_CLK>,
					<&nsscc NSS_CC_PORT5_RX_CLK_SRC>,
					<&nsscc NSS_CC_PORT5_TX_CLK_SRC>;
				clock-names = "cmn_ahb_clk",
					"cmn_sys_clk",
					"uniphy0_ahb_clk",
					"uniphy0_sys_clk",
					"uniphy1_ahb_clk",
					"uniphy1_sys_clk",
					"uniphy2_ahb_clk",
					"uniphy2_sys_clk",
					"gcc_nssnoc_nsscc_clk",
					"gcc_nsscc_clk",
					"gcc_nssnoc_snoc_1_clk",
					"gcc_nssnoc_snoc_clk",
					"port1_mac_clk",
					"port2_mac_clk",
					"port3_mac_clk",
					"port4_mac_clk",
					"port5_mac_clk",
					"port6_mac_clk",
					"nss_ppe_clk",
					"nss_ppe_cfg_clk",
					"nssnoc_ppe_clk",
					"nssnoc_ppe_cfg_clk",
					"nss_edma_clk",
					"nss_edma_cfg_clk",
					"nss_ppe_ipe_clk",
					"nss_ppe_btq_clk",
					"nss_port1_rx_clk", "nss_port1_tx_clk",
					"nss_port2_rx_clk", "nss_port2_tx_clk",
					"nss_port3_rx_clk", "nss_port3_tx_clk",
					"nss_port4_rx_clk", "nss_port4_tx_clk",
					"nss_port5_rx_clk", "nss_port5_tx_clk",
					"nss_port6_rx_clk", "nss_port6_tx_clk",
					"uniphy0_port1_rx_clk",
					"uniphy0_port1_tx_clk",
					"uniphy0_port2_rx_clk",
					"uniphy0_port2_tx_clk",
					"uniphy0_port3_rx_clk",
					"uniphy0_port3_tx_clk",
					"uniphy0_port4_rx_clk",
					"uniphy0_port4_tx_clk",
					"uniphy0_port5_rx_clk",
					"uniphy0_port5_tx_clk",
					"uniphy2_port6_rx_clk",
					"uniphy2_port6_tx_clk",
					"nss_port5_rx_clk_src",
					"nss_port5_tx_clk_src";
				resets = <&nsscc PPE_FULL_RESET>,
					<&nsscc UNIPHY0_SOFT_RESET>,
					<&gcc GCC_UNIPHY0_XPCS_RESET>,
					<&nsscc UNIPHY_PORT5_ARES>,
					<&gcc GCC_UNIPHY1_XPCS_RESET>,
					<&nsscc UNIPHY_PORT6_ARES>,
					<&gcc GCC_UNIPHY2_XPCS_RESET>,
					<&nsscc UNIPHY_PORT1_ARES>,
					<&nsscc UNIPHY_PORT2_ARES>,
					<&nsscc UNIPHY_PORT3_ARES>,
					<&nsscc UNIPHY_PORT4_ARES>,
					<&gcc GCC_UNIPHY0_SYS_RESET>,
					<&gcc GCC_UNIPHY1_SYS_RESET>,
					<&gcc GCC_UNIPHY2_SYS_RESET>,
					<&nsscc NSSPORT1_RESET>,
					<&nsscc NSSPORT2_RESET>,
					<&nsscc NSSPORT3_RESET>,
					<&nsscc NSSPORT4_RESET>,
					<&nsscc NSSPORT5_RESET>,
					<&nsscc NSSPORT6_RESET>,
					<&nsscc PORT1_MAC_ARES>,
					<&nsscc PORT2_MAC_ARES>,
					<&nsscc PORT3_MAC_ARES>,
					<&nsscc PORT4_MAC_ARES>,
					<&nsscc PORT5_MAC_ARES>,
					<&nsscc PORT6_MAC_ARES>;
				reset-names = "ppe_rst",
					"uniphy0_soft_rst",
					"uniphy0_xpcs_rst",
					"uniphy1_soft_rst",
					"uniphy1_xpcs_rst",
					"uniphy2_soft_rst",
					"uniphy2_xpcs_rst",
					"uniphy0_port1_dis",
					"uniphy0_port2_dis",
					"uniphy0_port3_dis",
					"uniphy0_port4_dis",
					"uniphy0_sys_rst",
					"uniphy1_sys_rst",
					"uniphy2_sys_rst",
					"nss_port1_rst",
					"nss_port2_rst",
					"nss_port3_rst",
					"nss_port4_rst",
					"nss_port5_rst",
					"nss_port6_rst",
					"nss_port1_mac_rst",
					"nss_port2_mac_rst",
					"nss_port3_mac_rst",
					"nss_port4_mac_rst",
					"nss_port5_mac_rst",
					"nss_port6_mac_rst";
				port_scheduler_resource {
					port@0 {
						port_id = <0>;
						ucast_queue = <0 63>;
						mcast_queue = <256 263>;
						l0sp = <0 0>;
						l0cdrr = <0 7>;
						l0edrr = <0 7>;
						l1cdrr = <0 0>;
						l1edrr = <0 0>;
					};
					port@1 {
						port_id = <1>;
						ucast_queue = <204 211>;
						mcast_queue = <272 275>;
						l0sp = <51 52>;
						l0cdrr = <108 115>;
						l0edrr = <108 115>;
						l1cdrr = <23 24>;
						l1edrr = <23 24>;
					};
					port@2 {
						port_id = <2>;
						ucast_queue = <212 219>;
						mcast_queue = <276 279>;
						l0sp = <53 54>;
						l0cdrr = <116 123>;
						l0edrr = <116 123>;
						l1cdrr = <25 26>;
						l1edrr = <25 26>;
					};
					port@3 {
						port_id = <3>;
						ucast_queue = <220 227>;
						mcast_queue = <280 283>;
						l0sp = <55 56>;
						l0cdrr = <124 131>;
						l0edrr = <124 131>;
						l1cdrr = <27 28>;
						l1edrr = <27 28>;
					};
					port@4 {
						port_id = <4>;
						ucast_queue = <228 235>;
						mcast_queue = <284 287>;
						l0sp = <57 58>;
						l0cdrr = <132 139>;
						l0edrr = <132 139>;
						l1cdrr = <29 30>;
						l1edrr = <29 30>;
					};
					port@5 {
						port_id = <5>;
						ucast_queue = <236 243>;
						mcast_queue = <288 291>;
						l0sp = <59 60>;
						l0cdrr = <140 147>;
						l0edrr = <140 147>;
						l1cdrr = <31 32>;
						l1edrr = <31 32>;
					};
					port@6 {
						port_id = <6>;
						ucast_queue = <244 251>;
						mcast_queue = <292 295>;
						l0sp = <61 62>;
						l0cdrr = <148 155>;
						l0edrr = <148 155>;
						l1cdrr = <33 34>;
						l1edrr = <33 34>;
					};
					port@7 {
						port_id = <7>;
						ucast_queue = <252 255>;
						mcast_queue = <296 299>;
						l0sp = <63 63>;
						l0cdrr = <156 159>;
						l0edrr = <156 159>;
						l1cdrr = <35 35>;
						l1edrr = <35 35>;
					};
					reserved {
						ucast_queue = <64 203>;
						mcast_queue = <264 271>;
						l0sp = <1 50>;
						l0cdrr = <8 107>;
						l0edrr = <8 107>;
						l1cdrr = <1 22>;
						l1edrr = <1 22>;
					};
				};
				port_scheduler_config {
					port@0 {
						port_id = <0>;
						l1scheduler {
							group@0 {
								/* L0 SP */
								sp = <0>;
								/* cpri cdrr epri edrr */
								cfg = <0 0 0 0>;
							};
						};
						l0scheduler {
							group@0 {
								/* unicast queue */
								ucast_queue = <0>;
								ucast_loop_pri = <8>;
								/* multicast queue */
								mcast_queue = <256>;
								/* sp cpri cdrr epri edrr */
								cfg = <0 0 0 0 0>;
							};
							group@1 {
								ucast_queue = <8>;
								ucast_loop_pri = <8>;
								mcast_queue = <257>;
								cfg = <0 0 0 0 0>;
							};
							group@2 {
								ucast_queue = <16>;
								ucast_loop_pri = <8>;
								mcast_queue = <258>;
								cfg = <0 0 0 0 0>;
							};
							group@3 {
								ucast_queue = <24>;
								ucast_loop_pri = <8>;
								mcast_queue = <259>;
								cfg = <0 0 0 0 0>;
							};
							group@4 {
								ucast_queue = <32>;
								ucast_loop_pri = <8>;
								mcast_queue = <260>;
								cfg = <0 0 0 0 0>;
							};
							group@5 {
								ucast_queue = <40>;
								ucast_loop_pri = <8>;
								mcast_queue = <261>;
								cfg = <0 0 0 0 0>;
							};
							group@6 {
								ucast_queue = <48>;
								ucast_loop_pri = <8>;
								mcast_queue = <262>;
								cfg = <0 0 0 0 0>;
							};
							group@7 {
								ucast_queue = <56>;
								ucast_loop_pri = <8>;
								mcast_queue = <263>;
								cfg = <0 0 0 0 0>;
							};
						};
					};
					port@1 {
						port_id = <1>;
						l1scheduler {
							group@0 {
								sp = <51>;
								cfg = <0 23 0 23>;
							};
							group@1 {
								sp = <52>;
								cfg = <1 24 1 24>;
							};
						};
						l0scheduler {
							group@0 {
								ucast_queue = <204>;
								ucast_loop_pri = <8>;
								/* max priority per SP */
								ucast_max_pri = <4>;
								mcast_queue = <272>;
								mcast_loop_pri = <4>;
								cfg = <51 0 108 0 108>;
							};
						};
					};
					port@2 {
						port_id = <2>;
						l1scheduler {
							group@0 {
								sp = <53>;
								cfg = <0 25 0 25>;
							};
							group@1 {
								sp = <54>;
								cfg = <1 26 1 26>;
							};
						};
						l0scheduler {
							group@0 {
								ucast_queue = <212>;
								ucast_loop_pri = <8>;
								ucast_max_pri = <4>;
								mcast_queue = <276>;
								mcast_loop_pri = <4>;
								cfg = <53 0 116 0 116>;
							};
						};
					};
					port@3 {
						port_id = <3>;
						l1scheduler {
							group@0 {
								sp = <55>;
								cfg = <0 27 0 27>;
							};
							group@1 {
								sp = <56>;
								cfg = <1 28 1 28>;
							};
						};
						l0scheduler {
							group@0 {
								ucast_queue = <220>;
								ucast_loop_pri = <8>;
								ucast_max_pri = <4>;
								mcast_queue = <280>;
								mcast_loop_pri = <4>;
								cfg = <55 0 124 0 124>;
							};
						};
					};
					port@4 {
						port_id = <4>;
						l1scheduler {
							group@0 {
								sp = <57>;
								cfg = <0 29 0 29>;
							};
							group@1 {
								sp = <58>;
								cfg = <1 30 1 30>;
							};
						};
						l0scheduler {
							group@0 {
								ucast_queue = <228>;
								ucast_loop_pri = <8>;
								ucast_max_pri = <4>;
								mcast_queue = <284>;
								mcast_loop_pri = <4>;
								cfg = <57 0 132 0 132>;
							};
						};
					};
					port@5 {
						port_id = <5>;
						l1scheduler {
							group@0 {
								sp = <59>;
								cfg = <0 31 0 31>;
							};
							group@1 {
								sp = <60>;
								cfg = <1 32 1 32>;
							};
						};
						l0scheduler {
							group@0 {
								ucast_queue = <236>;
								ucast_loop_pri = <8>;
								ucast_max_pri = <4>;
								mcast_queue = <288>;
								mcast_loop_pri = <4>;
								cfg = <59 0 140 0 140>;
							};
						};
					};
					port@6 {
						port_id = <6>;
						l1scheduler {
							group@0 {
								sp = <61>;
								cfg = <0 33 0 33>;
							};
							group@1 {
								sp = <62>;
								cfg = <1 34 1 34>;
							};
						};
						l0scheduler {
							group@0 {
								ucast_queue = <244>;
								ucast_loop_pri = <8>;
								ucast_max_pri = <4>;
								mcast_queue = <292>;
								mcast_loop_pri = <4>;
								cfg = <61 0 148 0 148>;
							};
						};
					};
					port@7 {
						port_id = <7>;
						l1scheduler {
							group@0 {
								sp = <63>;
								cfg = <0 35 0 35>;
							};
						};
						l0scheduler {
							group@0 {
								ucast_queue = <252>;
								ucast_loop_pri = <4>;
								ucast_max_pri = <4>;
								mcast_queue = <296>;
								mcast_loop_pri = <4>;
								cfg = <63 0 156 0 156>;
							};
						};
					};
				};
			};
		};

		ess-uniphy@7a00000 {
			compatible = "qcom,ess-uniphy";
			reg = <0x7a00000 0x30000>;
			uniphy_access_mode = "local bus";
		};

		q6v5_wcss: remoteproc@cd00000 {
			compatible = "qcom,ipq9574-q6-mpd";
			#address-cells = <1>;
			#size-cells = <1>;
			ranges;
			reg = <0x0cd00000 0x4040>,
			      <0xCB50000 0x8>;
			reg-names = "qdsp6",
				    "wcmn";
			interrupts-extended = <&intc GIC_SPI 325 IRQ_TYPE_EDGE_RISING>,
					      <&wcss_smp2p_in 0 0>,
					      <&wcss_smp2p_in 1 0>,
					      <&wcss_smp2p_in 2 0>,
					      <&wcss_smp2p_in 3 0>;
			interrupt-names = "wdog",
					  "fatal",
					  "ready",
					  "handover",
					  "stop-ack";

			clocks = <&gcc GCC_ANOC_WCSS_AXI_M_CLK>,
				 <&gcc GCC_WCSS_AHB_S_CLK>,
				 <&gcc GCC_WCSS_ECAHB_CLK>,
				 <&gcc GCC_WCSS_ACMT_CLK>,
				 <&gcc GCC_WCSS_AXI_M_CLK>,
				 <&gcc GCC_Q6_AXIM_CLK>,
				 <&gcc GCC_Q6_AXIM2_CLK>,
				 <&gcc GCC_Q6_AHB_CLK>,
				 <&gcc GCC_Q6_AHB_S_CLK>,
				 <&gcc GCC_Q6SS_BOOT_CLK>,
				 <&gcc GCC_WCSS_DBG_IFC_APB_BDG_CLK>,
				 <&gcc GCC_WCSS_DBG_IFC_ATB_BDG_CLK>,
				 <&gcc GCC_WCSS_DBG_IFC_DAPBUS_BDG_CLK>,
				 <&gcc GCC_WCSS_DBG_IFC_NTS_BDG_CLK>,
				 <&gcc GCC_WCSS_DBG_IFC_APB_CLK>,
				 <&gcc GCC_WCSS_DBG_IFC_ATB_CLK>,
				 <&gcc GCC_WCSS_DBG_IFC_DAPBUS_CLK>,
				 <&gcc GCC_WCSS_DBG_IFC_NTS_CLK>,
				 <&gcc GCC_Q6_TSCTR_1TO2_CLK>,
				 <&gcc GCC_Q6SS_ATBM_CLK>,
				 <&gcc GCC_Q6SS_PCLKDBG_CLK>,
				 <&gcc GCC_Q6SS_TRIG_CLK>,
				 <&gcc GCC_MEM_NOC_Q6_AXI_CLK>,
				 <&gcc GCC_WCSS_Q6_TBU_CLK>,
				 <&gcc GCC_SYS_NOC_WCSS_AHB_CLK>;

			clock-names = "anoc_wcss_axi_m",
				      "wcss_ahb_s",
				      "wcss_ecahb",
				      "wcss_acmt",
				      "wcss_axi_m",
				      "q6_axim",
				      "q6_axim2",
				      "q6_ahb",
				      "q6_ahb_s",
				      "q6ss_boot",
				      "dbg-apb-bdg",
				      "dbg-atb-bdg",
				      "dbg-dapbus-bdg",
				      "dbg-nts-bdg",
				      "dbg-apb",
				      "dbg-atb",
				      "dbg-dapbus",
				      "dbg-nts",
				      "q6_tsctr_1to2_clk",
				      "q6ss_atbm_clk",
				      "q6ss_pclkdbg_clk",
				      "q6ss_trig_clk",
				      "mem_noc_q6_axi",
				      "wcss_q6_tbu",
				      "sys_noc_wcss_ahb";

			assigned-clocks = <&gcc GCC_ANOC_WCSS_AXI_M_CLK>,
				 <&gcc GCC_WCSS_AHB_S_CLK>,
				 <&gcc GCC_WCSS_ECAHB_CLK>,
				 <&gcc GCC_WCSS_ACMT_CLK>,
				 <&gcc GCC_WCSS_AXI_M_CLK>,
				 <&gcc GCC_Q6_AXIM_CLK>,
				 <&gcc GCC_Q6_AXIM2_CLK>,
				 <&gcc GCC_Q6_AHB_CLK>,
				 <&gcc GCC_Q6_AHB_S_CLK>,
				 <&gcc GCC_Q6SS_BOOT_CLK>,
				 <&gcc GCC_MEM_NOC_Q6_AXI_CLK>,
				 <&gcc GCC_WCSS_Q6_TBU_CLK>,
				 <&gcc GCC_SYS_NOC_WCSS_AHB_CLK>;

			assigned-clock-rates = <266666667>,
						<133333333>,
						<133333333>,
						<133333333>,
						<266666667>,
						<533000000>,
						<342857143>,
						<133333333>,
						<133333333>,
						<342857143>,
						<533000000>,
						<533000000>,
						<133333333>;

			qcom,smem-states = <&wcss_smp2p_out 0>,
					   <&wcss_smp2p_out 1>;
			qcom,smem-state-names = "shutdown",
						"stop";

			memory-region = <&q6_region>;
			status = "disabled";

			glink-edge {
				interrupts = <GIC_SPI 321 IRQ_TYPE_EDGE_RISING>;
				label = "rtr";
				qcom,remote-pid = <1>;
				mboxes = <&apcs_glb 8>;
			};

			q6_wcss_pd1: remoteproc_pd1 {
				compatible = "qcom,ipq9574-wcss-ahb-mpd";
				m3_firmware = "IPQ9574/m3_fw.mdt";
			};
		};

		timer@b120000 {
			compatible = "arm,armv7-timer-mem";
			reg = <0x0b120000 0x1000>;
			#address-cells = <1>;
			#size-cells = <1>;
			ranges;

			frame@b120000 {
				reg = <0x0b121000 0x1000>,
				      <0x0b122000 0x1000>;
				frame-number = <0>;
				interrupts = <GIC_SPI 8 IRQ_TYPE_LEVEL_HIGH>,
					     <GIC_SPI 7 IRQ_TYPE_LEVEL_HIGH>;
			};

			frame@b123000 {
				reg = <0x0b123000 0x1000>;
				frame-number = <1>;
				interrupts = <GIC_SPI 9 IRQ_TYPE_LEVEL_HIGH>;
				status = "disabled";
			};

			frame@b124000 {
				reg = <0x0b124000 0x1000>;
				frame-number = <2>;
				interrupts = <GIC_SPI 10 IRQ_TYPE_LEVEL_HIGH>;
				status = "disabled";
			};

			frame@b125000 {
				reg = <0x0b125000 0x1000>;
				frame-number = <3>;
				interrupts = <GIC_SPI 11 IRQ_TYPE_LEVEL_HIGH>;
				status = "disabled";
			};

			frame@b126000 {
				reg = <0x0b126000 0x1000>;
				frame-number = <4>;
				interrupts = <GIC_SPI 12 IRQ_TYPE_LEVEL_HIGH>;
				status = "disabled";
			};

			frame@b127000 {
				reg = <0x0b127000 0x1000>;
				frame-number = <5>;
				interrupts = <GIC_SPI 13 IRQ_TYPE_LEVEL_HIGH>;
				status = "disabled";
			};

			frame@b128000 {
				reg = <0x0b128000 0x1000>;
				frame-number = <6>;
				interrupts = <GIC_SPI 14 IRQ_TYPE_LEVEL_HIGH>;
				status = "disabled";
			};
		};

		edma@3ab00000 {
			compatible = "qcom,edma";
			reg = <0x3ab00000 0xef800>;
			reg-names = "edma-reg-base";
			resets = <&nsscc EDMA_HW_RESET>;
			reset-names = "edma_rst";
			clocks = <&nsscc NSS_CC_NSS_CSR_CLK>,
				 <&nsscc NSS_CC_NSSNOC_NSS_CSR_CLK>,
				 <&nsscc NSS_CC_IMEM_QSB_CLK>,
				 <&nsscc NSS_CC_NSSNOC_IMEM_QSB_CLK>,
				 <&nsscc NSS_CC_IMEM_AHB_CLK>,
				 <&nsscc NSS_CC_NSSNOC_IMEM_AHB_CLK>,
				 <&nsscc NSS_CC_PPE_EDMA_CLK>,
				 <&gcc GCC_MEM_NOC_NSSNOC_CLK>,
				 <&gcc GCC_NSS_TBU_CLK>,
				 <&gcc GCC_NSS_TS_CLK>,
				 <&gcc GCC_NSSCC_CLK>,
				 <&gcc GCC_NSSCFG_CLK>,
				 <&gcc GCC_NSSNOC_ATB_CLK>,
				 <&gcc GCC_NSSNOC_MEM_NOC_1_CLK>,
				 <&gcc GCC_NSSNOC_MEMNOC_CLK>,
				 <&gcc GCC_NSSNOC_NSSCC_CLK>,
				 <&gcc GCC_NSSNOC_PCNOC_1_CLK>,
				 <&gcc GCC_NSSNOC_QOSGEN_REF_CLK>,
				 <&gcc GCC_NSSNOC_SNOC_1_CLK>,
				 <&gcc GCC_NSSNOC_SNOC_CLK>,
				 <&gcc GCC_NSSNOC_TIMEOUT_REF_CLK>,
				 <&gcc GCC_NSSNOC_XO_DCD_CLK>;
			clock-names = "nss-csr-clk", "nss-nssnoc-csr-clk",
				      "nss-imem-qsb-clk", "nss-nssnoc-imem-qsb-clk",
				      "nss-imem-ahb-clk", "nss-nssnoc-imem-ahb-clk", "nss-edma-clk",
				      "nss-mem-noc-nssnoc-clk", "nss-tbu-clk", "nss-ts-clk",
				      "nss-nsscc-clk", "nss-nsscfg-clk", "nss-nsscnoc-atb-clk",
				      "nss-nssnoc-mem-noc-1-clk", "nss-nssnoc-memnoc-clk", "nss-nssnoc-nsscc-clk",
				      "nss-nssnoc-pcnoc-1-clk", "nss-nssnoc-qosgen-ref-clk", "nss-nssnoc-snoc-1-clk",
				      "nss-nssnoc-snoc-clk", "nss-nssnoc-timeout-ref-clk", "nss-nssnoc-xo-dcd-clk";
		};

		nss-ppe {
			compatible = "qcom,nss-ppe";
		};

		eip: eip197@39800000 {
			compatible = "qcom,eip";
			reg-names = "eip_pbase";
			reg = <0x39800000 0x7ffff>;
			reg_offset = <0x80000>;
			ranges;
			clocks = <&nsscc NSS_CC_CRYPTO_CLK>,
			<&nsscc NSS_CC_NSSNOC_CRYPTO_CLK>,
			<&nsscc NSS_CC_CRYPTO_PPE_CLK>;
			clock-names = "crypto_clk", "crypto_nocclk",
			"crypto_ppeclk";
			clock-frequency = /bits/ 64 <600000000 600000000 300000000>;
			qcom,inline-enabled;
			interrupts = <GIC_SPI 385 IRQ_TYPE_LEVEL_HIGH>,
				   <GIC_SPI 386 IRQ_TYPE_LEVEL_HIGH>,
				   <GIC_SPI 387 IRQ_TYPE_LEVEL_HIGH>,
				   <GIC_SPI 388 IRQ_TYPE_LEVEL_HIGH>;
			status = "okay";

			dma0 {
				tx_cpu = /bits/ 8 <0>;
				rx_cpu = /bits/ 8 <0>;
				ring-name = "lookaside";
				ring-id = /bits/ 8 <0>;
			};

			dma1 {
				tx_cpu = /bits/ 8 <1>;
				rx_cpu = /bits/ 8 <1>;
				ring-name = "lookaside";
				ring-id = /bits/ 8 <1>;
			};

			dma2 {
				tx_cpu = /bits/ 8 <2>;
				rx_cpu = /bits/ 8 <2>;
				ring-name = "lookaside";
				ring-id = /bits/ 8 <2>;
			};

			dma3 {
				tx_cpu = /bits/ 8 <3>;
				rx_cpu = /bits/ 8 <3>;
				ring-name = "lookaside";
				ring-id = /bits/ 8 <3>;
			};

			dma4 {
				tx_cpu = /bits/ 8 <0>;
				rx_cpu = /bits/ 8 <0>;
				ring-name = "hybrid";
				ring-id = /bits/ 8 <4>;
			};

			dma5 {
				tx_cpu = /bits/ 8 <1>;
				rx_cpu = /bits/ 8 <1>;
				ring-name = "hybrid";
				ring-id = /bits/ 8 <5>;
			};

			dma6 {
				tx_cpu = /bits/ 8 <2>;
				rx_cpu = /bits/ 8 <2>;
				ring-name = "hybrid";
				ring-id = /bits/ 8 <6>;
			};

			dma7 {
				tx_cpu = /bits/ 8 <3>;
				rx_cpu = /bits/ 8 <3>;
				ring-name = "hybrid";
				ring-id = /bits/ 8 <7>;
			};
		};

		eip_crypto: eip_crypto {
			compatible = "qcom,eip_crypto";
			status = "okay";
		};

		stm: stm@6002000 {
			compatible = "arm,coresight-stm", "arm,primecell";
			reg = <0x6002000 0x1000>,
				<0x9280000 0x180000>;
			reg-names = "stm-base", "stm-stimulus-base";
			coresight-name = "coresight-stm";
			clocks = <&gcc GCC_QDSS_DAP_CLK>,
				 <&gcc GCC_QDSS_AT_CLK>;
			clock-names = "apb_pclk", "atclk";

			assigned-clocks = <&gcc GCC_QDSS_DAP_CLK>,
				 <&gcc GCC_QDSS_AT_CLK>;

			assigned-clock-rates = <150000000>,
						<240000000>;
			out-ports {
				port {
					stm_out: endpoint {
						remote-endpoint = <&funnel0_in7>;
					};
				};
			};
		};

		funnel_in0: funnel@6041000 {
			compatible = "arm,coresight-dynamic-funnel", "arm,primecell";
			reg = <0x6041000 0x1000>;
			reg-names = "funnel-base";
			coresight-name = "coresight-funnel-in0";
			clocks = <&gcc GCC_QDSS_DAP_CLK>,
				 <&gcc GCC_QDSS_AT_CLK>;
			clock-names = "apb_pclk", "atclk";

			in-ports {
				#address-cells = <1>;
				#size-cells = <0>;

				/** Port 0 - RPM ETM
				 * Port 1 - RPM ITM
				 * Port 2 - SNOC
				 * Port 3 - TME Funnel
				 * Port 4 - PCNOC
				 * Port 5 - MEMNOC
				 * Port 6 - TPDA QDSS
				 */

				port@7 {
					reg = <7>;
					funnel0_in7: endpoint {
						remote-endpoint = <&stm_out>;
					};
				};
			};

			out-ports {
				port {
					funnel0_out: endpoint {
						remote-endpoint = <&merge_funnel_in0>;
					};
				};
			};
		};

		funnel_in1: funnel@6042000 {
			compatible = "arm,coresight-dynamic-funnel", "arm,primecell";
			reg = <0x6042000 0x1000>;
			reg-names = "funnel-base";
			coresight-name = "coresight-funnel-in1";
			clocks = <&gcc GCC_QDSS_DAP_CLK>,
				 <&gcc GCC_QDSS_AT_CLK>;
			clock-names = "apb_pclk", "atclk";

			in-ports {
				#address-cells = <1>;
				#size-cells = <0>;

				/** Port 0 - NA
				 * Port 1 - WCSS Q6
				 * Port 2 - APSS FUNNEL
				 * Port 3 - WCSS Core
				 * Port 4 - NSS Funnel
				 * Port 5 - WCSS Q6 M2
				 * Port 6 - TPDA QDSS Wrapper
				 */

				port@2 {
					reg = <2>;
					funnel1_in2: endpoint {
						remote-endpoint = <&apss_funnel_out>;
					};
				};
			};

			out-ports {
				port {
					funnel1_out: endpoint {
						remote-endpoint = <&merge_funnel_in1>;
					};
				};
			};

		};

		funnel_merge: funnel@6045000 {
			compatible = "arm,coresight-dynamic-funnel", "arm,primecell";
			reg = <0x6045000 0x1000>;
			reg-names = "funnel-base";
			coresight-name = "coresight-funnel-merge";
			clocks = <&gcc GCC_QDSS_DAP_CLK>,
				 <&gcc GCC_QDSS_AT_CLK>;
			clock-names = "apb_pclk", "atclk";

			out-ports {
				port {
					merge_funnel_out: endpoint {
						remote-endpoint = <&etf_in>;
					};
				};
			};

			in-ports {
				#address-cells = <1>;
				#size-cells = <0>;

				port@0 {
					reg = <0>;
					merge_funnel_in0: endpoint {
						remote-endpoint = <&funnel0_out>;
					};
				};

				port@1 {
					reg = <1>;
					merge_funnel_in1: endpoint {
						remote-endpoint = <&funnel1_out>;
					};
				};
			};

		};

		etr_replicator: replicator@6046000 {
			compatible = "arm,coresight-dynamic-replicator", "arm,primecell";
			reg = <0x6046000 0x1000>;
			reg-names = "replicator-base";
			coresight-name = "coresight-replicator";
			clocks = <&gcc GCC_QDSS_DAP_CLK>,
				 <&gcc GCC_QDSS_AT_CLK>;
			clock-names = "apb_pclk", "atclk";

			out-ports {
				#address-cells = <1>;
				#size-cells = <0>;

				port@0 {
					reg = <0>;
					etr_replicator_out0: endpoint {
						remote-endpoint = <&etr_in>;
					};
				};
			};

			in-ports {
				port {
					etr_replicator_in0: endpoint {
						remote-endpoint = <&etf_out>;
					};
				};
			};
		};

		etf@6047000 {
			compatible = "arm,coresight-tmc", "arm,primecell";
			reg = <0x6047000 0x1000>;
			reg-names = "tmc-base";
			coresight-name = "coresight-tmc-etf";
			arm,default-sink;
			clocks = <&gcc GCC_QDSS_DAP_CLK>;
			clock-names = "apb_pclk";

			out-ports {
				port {
					etf_out: endpoint {
						remote-endpoint = <&etr_replicator_in0>;
					};
				};
			};

			in-ports {
				port {
					etf_in: endpoint {
						remote-endpoint = <&merge_funnel_out>;
					};
				};
			};
		};

		tmc_etr: tmc@6048000 {
			compatible = "arm,coresight-tmc", "arm,primecell";
			reg = <0x6048000 0x1000>,
				<0x6064000  0x15000>;
			reg-names = "tmc-base", "bam-base";
			interrupts = <GIC_SPI 166 IRQ_TYPE_EDGE_RISING>;
			interrupt-names = "byte-cntr-irq";
			arm,buffer-size = <0x100000>;
			arm,scatter-gather;
			memory-region = <&q6_etr_region>;
			coresight-name = "coresight-tmc-etr";
			clocks = <&gcc GCC_QDSS_DAP_CLK>;
			clock-names = "apb_pclk";

			in-ports {
				port {
					etr_in: endpoint {
						remote-endpoint = <&etr_replicator_out0>;
					};
				};
			};
		};

		etm0: etm@6293000 {
			compatible = "arm,coresight-etm4x", "arm,primecell";
			reg = <0x6293000 0x1000>;
			coresight-name = "coresight-etm0";
			cpu = <&CPU0>;
			clocks = <&gcc GCC_QDSS_DAP_CLK>;
			clock-names = "apb_pclk";

			out-ports {
				port {
					etm0_out: endpoint {
						remote-endpoint = <&apss_funnel_in0>;
					};
				};
			};
		};

		etm1: etm@6297000 {
			compatible = "arm,coresight-etm4x", "arm,primecell";
			reg = <0x6297000 0x1000>;
			coresight-name = "coresight-etm1";
			cpu = <&CPU1>;
			clocks = <&gcc GCC_QDSS_DAP_CLK>;
			clock-names = "apb_pclk";

			out-ports {
				port {
					etm1_out: endpoint {
						remote-endpoint = <&apss_funnel_in1>;
					};
				};
			};
		};

		etm2: etm@629b000 {
			compatible = "arm,coresight-etm4x", "arm,primecell";
			reg = <0x629b000 0x1000>;
			coresight-name = "coresight-etm2";
			cpu = <&CPU2>;
			clocks = <&gcc GCC_QDSS_DAP_CLK>;
			clock-names = "apb_pclk";

			out-ports {
				port {
					etm2_out: endpoint {
						remote-endpoint = <&apss_funnel_in2>;
					};
				};
			};
		};

		etm3: etm@629f000 {
			compatible = "arm,coresight-etm4x", "arm,primecell";
			reg = <0x629f000 0x1000>;
			coresight-name = "coresight-etm3";
			cpu = <&CPU3>;
			clocks = <&gcc GCC_QDSS_DAP_CLK>;
			clock-names = "apb_pclk";

			out-ports {
				port {
					etm3_out: endpoint {
						remote-endpoint = <&apss_funnel_in3>;
					};
				};
			};
		};

		funnel_apss: funnel@62a1000 {
			compatible = "arm,coresight-dynamic-funnel", "arm,primecell";
			reg = <0x62a1000 0x1000>;
			reg-names = "funnel-base";
			coresight-name = "coresight-funnel-apss";
			clocks = <&gcc GCC_QDSS_DAP_CLK>,
				 <&gcc GCC_QDSS_AT_CLK>;
			clock-names = "apb_pclk", "atclk";

			out-ports {
				port {
					apss_funnel_out: endpoint {
						remote-endpoint = <&funnel1_in2>;
					};
				};
			};

			in-ports {
				#address-cells = <1>;
				#size-cells = <0>;

				port@0 {
					reg = <0>;
					apss_funnel_in0: endpoint {
						remote-endpoint = <&etm0_out>;
					};
				};

				port@1 {
					reg = <1>;
					apss_funnel_in1: endpoint {
						remote-endpoint = <&etm1_out>;
					};
				};

				port@2 {
					reg = <2>;
					apss_funnel_in2: endpoint {
						remote-endpoint = <&etm2_out>;
					};
				};

				port@3 {
					reg = <3>;
					apss_funnel_in3: endpoint {
						remote-endpoint = <&etm3_out>;
					};
				};
			};
		};

	};

	thermal_zones: thermal-zones {
		nss-top-thermal {
			polling-delay-passive = <0>;
			polling-delay = <0>;
			thermal-sensors = <&tsens 3>;

			trips {
				nss-top-critical {
					temperature = <125000>;
					hysteresis = <9000>;
					type = "critical";
				};
			};
		};

		ubi-0-thermal {
			polling-delay-passive = <0>;
			polling-delay = <0>;
			thermal-sensors = <&tsens 4>;

			trips {
				ubi_0-critical {
					temperature = <125000>;
					hysteresis = <9000>;
					type = "critical";
				};
			};
		};

		ubi-1-thermal {
			polling-delay-passive = <0>;
			polling-delay = <0>;
			thermal-sensors = <&tsens 5>;

			trips {
				ubi_1-critical {
					temperature = <125000>;
					hysteresis = <9000>;
					type = "critical";
				};
			};
		};

		ubi-2-thermal {
			polling-delay-passive = <0>;
			polling-delay = <0>;
			thermal-sensors = <&tsens 6>;

			trips {
				ubi_2-critical {
					temperature = <125000>;
					hysteresis = <9000>;
					type = "critical";
				};
			};
		};

		ubi-3-thermal {
			polling-delay-passive = <0>;
			polling-delay = <0>;
			thermal-sensors = <&tsens 7>;

			trips {
				ubi_3-critical {
					temperature = <125000>;
					hysteresis = <9000>;
					type = "critical";
				};
			};
		};

		cpuss0-thermal {
			polling-delay-passive = <0>;
			polling-delay = <0>;
			thermal-sensors = <&tsens 8>;

			trips {
				cpu-critical {
					temperature = <125000>;
					hysteresis = <9000>;
					type = "critical";
				};
			};
		};

		cpuss1-thermal {
			polling-delay-passive = <0>;
			polling-delay = <0>;
			thermal-sensors = <&tsens 9>;

			trips {
				cpu-critical {
					temperature = <125000>;
					hysteresis = <9000>;
					type = "critical";
				};
			};
		};

		cpu0-thermal {
			polling-delay-passive = <0>;
			polling-delay = <0>;
			thermal-sensors = <&tsens 10>;

			trips {
				cpu-critical {
					temperature = <120000>;
					hysteresis = <9000>;
					type = "critical";
				};

				cpu-passive {
					temperature = <110000>;
					hysteresis = <9000>;
					type = "passive";
				};
			};
		};

		cpu1-thermal {
			polling-delay-passive = <0>;
			polling-delay = <0>;
			thermal-sensors = <&tsens 11>;

			trips {
				cpu-critical {
					temperature = <120000>;
					hysteresis = <9000>;
					type = "critical";
				};

				cpu-passive {
					temperature = <110000>;
					hysteresis = <9000>;
					type = "passive";
				};
			};
		};

		cpu2-thermal {
			polling-delay-passive = <0>;
			polling-delay = <0>;
			thermal-sensors = <&tsens 12>;

			trips {
				cpu-critical {
					temperature = <120000>;
					hysteresis = <9000>;
					type = "critical";
				};

				cpu-passive {
					temperature = <110000>;
					hysteresis = <9000>;
					type = "passive";
				};
			};
		};

		cpu3-thermal {
			polling-delay-passive = <0>;
			polling-delay = <0>;
			thermal-sensors = <&tsens 13>;

			trips {
				cpu-critical {
					temperature = <120000>;
					hysteresis = <9000>;
					type = "critical";
				};

				cpu3_thermal_alert: cpu-passive {
					temperature = <110000>;
					hysteresis = <9000>;
					type = "passive";
				};
			};

			cooling-maps {
				map0 {
					trip = <&cpu3_thermal_alert>;
					/* Set maximum frequency as 936 MHz  */
					cooling-device = <&CPU0 5 5>,
							 <&CPU1 5 5>,
							 <&CPU2 5 5>,
							 <&CPU3 5 5>;
				};
			};
		};

		wcss-phyb-thermal {
			polling-delay-passive = <0>;
			polling-delay = <0>;
			thermal-sensors = <&tsens 14>;

			trips {
				wcss_phyb-critical {
					temperature = <125000>;
					hysteresis = <9000>;
					type = "critical";
				};
			};
		};

		top-glue-thermal {
			polling-delay-passive = <0>;
			polling-delay = <0>;
			thermal-sensors = <&tsens 15>;

			trips {
				top_glue-critical {
					temperature = <125000>;
					hysteresis = <9000>;
					type = "critical";
				};
			};
		};
	};

	license_manager: license_manager {
		compatible = "qti,license-manager-service";
		license-file = "";
		status = "disabled";
	};

	timer {
		compatible = "arm,armv8-timer";
		interrupts = <GIC_PPI 2 (GIC_CPU_MASK_SIMPLE(4) | IRQ_TYPE_LEVEL_LOW)>,
			     <GIC_PPI 3 (GIC_CPU_MASK_SIMPLE(4) | IRQ_TYPE_LEVEL_LOW)>,
			     <GIC_PPI 4 (GIC_CPU_MASK_SIMPLE(4) | IRQ_TYPE_LEVEL_LOW)>,
			     <GIC_PPI 1 (GIC_CPU_MASK_SIMPLE(4) | IRQ_TYPE_LEVEL_LOW)>;
	};

	qcom,test@0 {
		compatible = "qcom,testmhi";
		qcom,wlan-ramdump-dynamic = <0x600000>;
	};
};

#include "ipq9574-cpr-regulator.dtsi"
#ifndef __CPU_THERMAL__
#include "ipq9574-thermald.dtsi"
#endif
